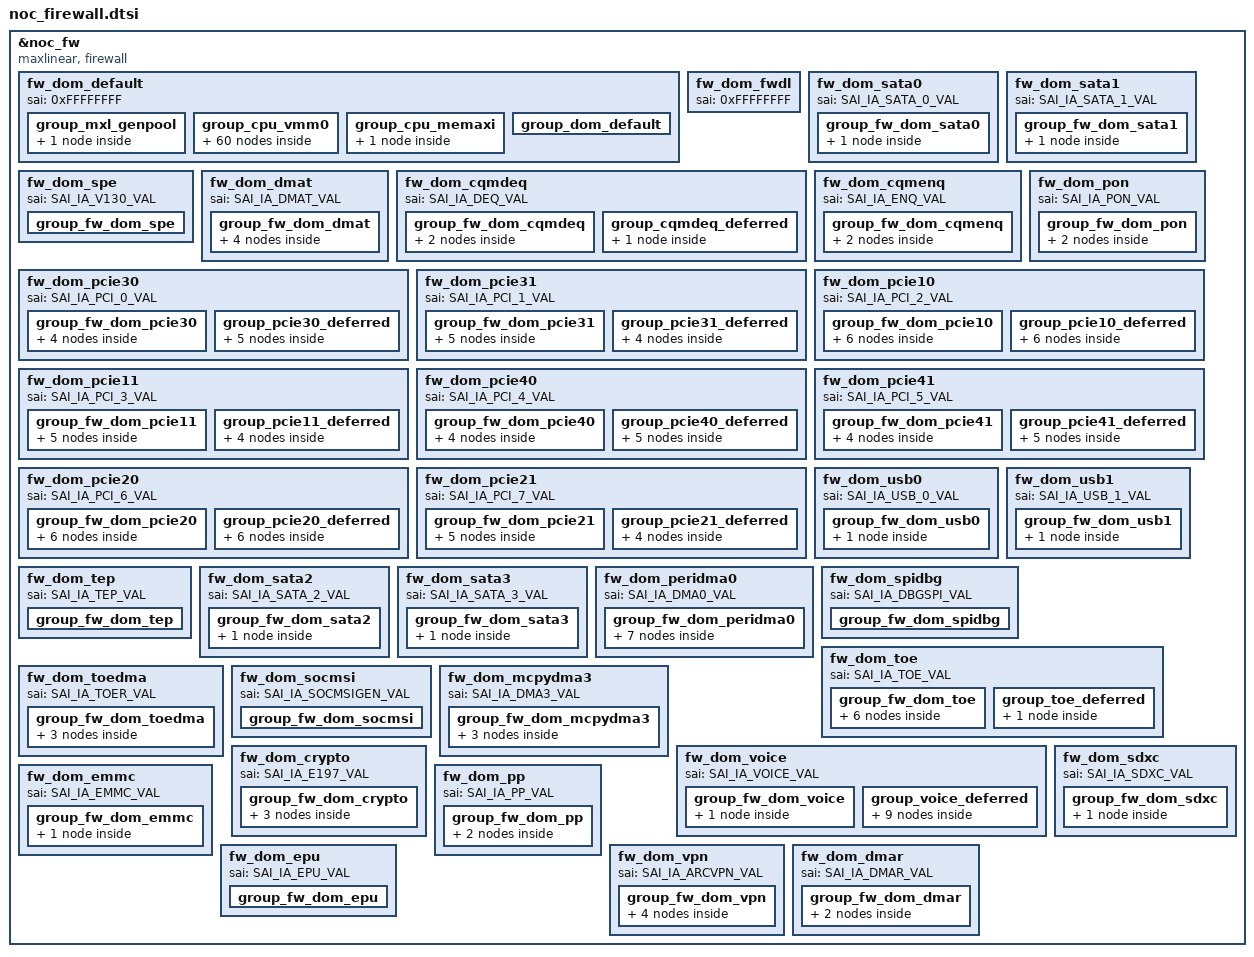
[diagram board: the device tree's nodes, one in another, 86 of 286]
// SPDX-License-Identifier: GPL-2.0
/**
 * Copyright (C) 2021 - 2024 MaxLinear, Inc.
 */
/* Based on released V3.0.31 version on Sep/13/2024 from Ritesh*/

#include <dt-bindings/soc/mxl,noc_fw_defs.h>

&noc_fw {
	compatible = "maxlinear, firewall";
	intel,socpool = <&cpu_pool &sys_pool &ro_pool &rw_pool &icc_pool>;

/* fw_dom_default must be defined in the DT */
	fw_dom_default:fw_dom_default {
		#firewall-domain-cells = <0>;
		sai = <0xFFFFFFFF>; /* special SAI */
		group_mxl_genpool {
		rule_mxl_genpool_1 { /*  8  in FW_DDR_Rules */
			op       = <NOC_FW_OP_MODIFY_SPLIT>;
			sai      = <SAI_IA_MEMAXI_VAL>;
			base     = <0xA0000000 NOC_FW_SYSPOOL_START>; /* NOC_FW_NONCOHERENT|NOC_FW_SPECIAL_REGION  NOC_FW_SYSPOOL_START */
			end      = <0xA0000000 NOC_FW_ROPOOL_END>; /* NOC_FW_NONCOHERENT|NOC_FW_SPECIAL_REGION  NOC_FW_ROPOOL_END */
			perm     = <NOC_FW_F_R>;
		};
		};
		group_cpu_vmm0 {
		rule_cpu_vmm0_1 { /*  12  in FW_LBAXI_Rules */
			op       = <NOC_FW_OP_ADD>;
			sai      = <ALL_SAI_IA_VMM_VAL>;
			target   = <&crypto>;
			base     = <0x0  0xED600000>;
			end      = <0x0  0xED6FFFFF>;
			perm     = <NOC_FW_F_RW>;
		};
		rule_cpu_vmm0_2 { /*  14  in FW_LBAXI_Rules */
			op       = <NOC_FW_OP_ADD>;
			sai      = <ALL_SAI_IA_VMM_VAL>;
			target   = <&mcpy>;
			base     = <0x0  0xED700000>;
			end      = <0x0  0xED70FFFF>;
			perm     = <NOC_FW_F_RW>;
		};
		rule_cpu_vmm0_3 { /*  15  in FW_LBAXI_Rules */
			op       = <NOC_FW_OP_ADD>;
			sai      = <ALL_SAI_IA_VMM_VAL>;
			target   = <&mcpy>;
			base     = <0x0  0xEC800000>;
			end      = <0x0  0xEC800FFF>;
			perm     = <NOC_FW_F_RW>;
		};
		rule_cpu_vmm0_4 { /*  16  in FW_LBAXI_Rules */
			op       = <NOC_FW_OP_ADD>;
			sai      = <ALL_SAI_IA_VMM_VAL>;
			target   = <&toe>;
			base     = <0x0  0xEC900000>;
			end      = <0x0  0xECBFFFFF>;
			perm     = <NOC_FW_F_RW>;
		};
		rule_cpu_vmm0_5 { /*  22  in FW_LBAXI_Rules */
			op       = <NOC_FW_OP_ADD>;
			sai      = <ALL_SAI_IA_VMM_VAL>;
			target   = <&sdxc>;
			base     = <0x0  0xEC600000>;
			end      = <0x0  0xEC6FFFFF>;
			perm     = <NOC_FW_F_RW>;
		};
		rule_cpu_vmm0_6 { /*  23  in FW_LBAXI_Rules */
			op       = <NOC_FW_OP_ADD>;
			sai      = <ALL_SAI_IA_VMM_VAL>;
			target   = <&ssx_voice>;
			base     = <0x0  0xED200000>;
			end      = <0x0  0xED480FFF>;
			perm     = <NOC_FW_F_RW>;
		};
		rule_cpu_vmm0_7 { /*  24  in FW_LBAXI_Rules */
			op       = <NOC_FW_OP_ADD>;
			sai      = <ALL_SAI_IA_VMM_VAL>;
			target   = <&combophy2>;
			base     = <0x0  0xC0A00000>;
			end      = <0x0  0xC0B43FFF>;
			perm     = <NOC_FW_F_RW>;
		};
		rule_cpu_vmm0_8 { /*  25  in FW_LBAXI_Rules */
			op       = <NOC_FW_OP_ADD>;
			sai      = <ALL_SAI_IA_VMM_VAL>;
			base     = <0x0  0xC0E00000>;
			end      = <0x0  0xC11FFFFF>;
			perm     = <NOC_FW_F_RW>;
		};

#ifndef LGMC_SOC
		rule_cpu_vmm0_9 { /*  29  in FW_LBAXI_Rules */
			op       = <NOC_FW_OP_ADD>;
			sai      = <ALL_SAI_IA_VMM_VAL>;
			target   = <&sata20>;
			base     = <0x0  0xC1A00000>;
			end      = <0x0  0xC1A000FF>;
			perm     = <NOC_FW_F_RW>;
		};
		rule_cpu_vmm0_10 { /*  30  in FW_LBAXI_Rules */
			op       = <NOC_FW_OP_ADD>;
			sai      = <ALL_SAI_IA_VMM_VAL>;
			target   = <&sata21>;
			base     = <0x0  0xC1B00000>;
			end      = <0x0  0xC1B000FF>;
			perm     = <NOC_FW_F_RW>;
		};
#endif

		rule_cpu_vmm0_11 { /*  31  in FW_LBAXI_Rules */
			op       = <NOC_FW_OP_ADD>;
			sai      = <ALL_SAI_IA_VMM_VAL>;
			target   = <&combophy0>;
			base     = <0x0  0xD0A00000>;
			end      = <0x0  0xD0B43FFF>;
			perm     = <NOC_FW_F_RW>;
		};
		rule_cpu_vmm0_12 { /*  32  in FW_LBAXI_Rules */
			op       = <NOC_FW_OP_ADD>;
			sai      = <ALL_SAI_IA_VMM_VAL>;
			base     = <0x0  0xD0E00000>;
			end      = <0x0  0xD11FFFFF>;
			perm     = <NOC_FW_F_RW>;
		};

#ifndef LGMC_SOC
		rule_cpu_vmm0_13 { /*  36  in FW_LBAXI_Rules */
			op       = <NOC_FW_OP_ADD>;
			sai      = <ALL_SAI_IA_VMM_VAL>;
			target   = <&sata10>;
			base     = <0x0  0xD1A00000>;
			end      = <0x0  0xD1A000FF>;
			perm     = <NOC_FW_F_RW>;
		};
		rule_cpu_vmm0_14 { /*  37  in FW_LBAXI_Rules */
			op       = <NOC_FW_OP_ADD>;
			sai      = <ALL_SAI_IA_VMM_VAL>;
			target   = <&sata11>;
			base     = <0x0  0xD1B00000>;
			end      = <0x0  0xD1B000FF>;
			perm     = <NOC_FW_F_RW>;
		};
#endif

		rule_cpu_vmm0_15 { /*  50  in FW_LBAXI_Rules */
			op       = <NOC_FW_OP_ADD>;
			sai      = <ALL_SAI_IA_VMM_VAL>;
			target   = <&ponmbox>;
			base     = <0x0  0xE7500000>;
			end      = <0x0  0xE7840FFF>;
			perm     = <NOC_FW_F_RW>;
		};
		rule_cpu_vmm0_16 { /*  51  in FW_LBAXI_Rules */
			op       = <NOC_FW_OP_ADD>;
			sai      = <ALL_SAI_IA_VMM_VAL>;
			target   = <&wan_xpcs>;
			base     = <0x0  0xE7842000>;
			end      = <0x0  0xE78440FF>;
			perm     = <NOC_FW_F_RW>;
		};
		rule_cpu_vmm0_17 { /*  52  in FW_LBAXI_Rules */
			op       = <NOC_FW_OP_ADD>;
			sai      = <ALL_SAI_IA_VMM_VAL>;
			target   = <&vpn>;
			base     = <0x0  0xE7B00000>;
			end      = <0x0  0xE7B01FFF>;
			perm     = <NOC_FW_F_RW>;
		};

#ifndef LGMC_SOC
		rule_cpu_vmm0_18 { /*  53  in FW_LBAXI_Rules */
			op       = <NOC_FW_OP_ADD>;
			sai      = <ALL_SAI_IA_VMM_VAL>;
			target   = <&usb0>;
			base     = <0x0  0xE7D00000>;
			end      = <0x0  0xE7D0DFFF>;
			perm     = <NOC_FW_F_RW>;
		};
		rule_cpu_vmm0_19 { /*  54  in FW_LBAXI_Rules */
			op       = <NOC_FW_OP_ADD>;
			sai      = <ALL_SAI_IA_VMM_VAL>;
			target   = <&usb0>;
			base     = <0x0  0xE7E00000>;
			end      = <0x0  0xE7E02FFF>;
			perm     = <NOC_FW_F_RW>;
		};
#endif

		rule_cpu_vmm0_20 { /*  55  in FW_LBAXI_Rules */
			op       = <NOC_FW_OP_ADD>;
			sai      = <ALL_SAI_IA_VMM_VAL>;
			target   = <&usb1>;
			base     = <0x0  0xE6E00000>;
			end      = <0x0  0xE6E0DFFF>;
			perm     = <NOC_FW_F_RW>;
		};
		rule_cpu_vmm0_21 { /*  56  in FW_LBAXI_Rules */
			op       = <NOC_FW_OP_ADD>;
			sai      = <ALL_SAI_IA_VMM_VAL>;
			target   = <&usb1>;
			base     = <0x0  0xE6F00000>;
			end      = <0x0  0xE6F02FFF>;
			perm     = <NOC_FW_F_RW>;
		};
		rule_cpu_vmm0_22 { /*  58  in FW_LBAXI_Rules */
			status = "disabled"; /* TEP_DEBUG2 */
			op       = <NOC_FW_OP_ADD>;
			sai      = <ALL_SAI_IA_VMM_VAL>;
			base     = <0x0  0xE0000000>;
			end      = <0x0  0xE0020FFF>;
			perm     = <NOC_FW_F_RW>;
		};
		rule_cpu_vmm0_23 { /*  59  in FW_LBAXI_Rules */
			op       = <NOC_FW_OP_MODIFY>;
			sai      = <ALL_SAI_IA_VMM_VAL>;
			base     = <0x0  0xE00E0000>;
			end      = <0x0  0xE00E0FFF>;
			perm     = <NOC_FW_F_RW>;
		};
		rule_cpu_vmm0_24 { /*  60  in FW_LBAXI_Rules */
			op       = <NOC_FW_OP_ADD>;
			sai      = <ALL_SAI_IA_VMM_VAL>;
			base     = <0x0  0xECF00000>;
			end      = <0x0  0xECF04FFF>;
			perm     = <NOC_FW_F_RW>;
		};
		rule_cpu_vmm0_25 { /*  65  in FW_LBAXI_Rules */
			op       = <NOC_FW_OP_ADD>;
			sai      = <ALL_SAI_IA_VMM_VAL>;
			base     = <0x0  0xE7140000>;
			end      = <0x0  0xE7153FFF>;
			perm     = <NOC_FW_F_RW>;
		};
		rule_cpu_vmm0_26 { /*  66  in FW_LBAXI_Rules */
			op       = <NOC_FW_OP_ADD>;
			sai      = <ALL_SAI_IA_VMM_VAL>;
			base     = <0x0  0xE7200000>;
			end      = <0x0  0xE7300FFF>;
			perm     = <NOC_FW_F_RW>;
		};
		rule_cpu_vmm0_27 { /*  67  in FW_LBAXI_Rules */
			op       = <NOC_FW_OP_ADD>;
			sai      = <ALL_SAI_IA_VMM_VAL>;
			target   = <&dma2tx>;
			base     = <0x0  0xE7000000>;
			end      = <0x0  0xE7000FFF>;
			perm     = <NOC_FW_F_RW>;
		};
		rule_cpu_vmm0_28 { /*  68  in FW_LBAXI_Rules */
			op       = <NOC_FW_OP_ADD>;
			sai      = <ALL_SAI_IA_VMM_VAL>;
			target   = <&dma0tx>;
			base     = <0x0  0xE7700000>;
			end      = <0x0  0xE7700FFF>;
			perm     = <NOC_FW_F_RW>;
		};
		rule_cpu_vmm0_29 { /*  69  in FW_LBAXI_Rules */
			op       = <NOC_FW_OP_ADD>;
			sai      = <ALL_SAI_IA_VMM_VAL>;
			base     = <0x0  0xE7600000>;
			end      = <0x0  0xE7642FFF>;
			perm     = <NOC_FW_F_RW>;
		};
		rule_cpu_vmm0_30 { /*  70  in FW_LBAXI_Rules */
			op       = <NOC_FW_OP_ADD>;
			sai      = <ALL_SAI_IA_VMM_VAL>;
			base     = <0x0  0xE7400000>;
			end      = <0x0  0xE742FFFF>;
			perm     = <NOC_FW_F_RW>;
		};
		rule_cpu_vmm0_31 { /*  72  in FW_LBAXI_Rules */
			op       = <NOC_FW_OP_ADD>;
			sai      = <ALL_SAI_IA_VMM_VAL>;
			base     = <0x0  0xD4000000>;
			end      = <0x0  0xDFFFFFFF>;
			perm     = <NOC_FW_F_RW>;
		};
		rule_cpu_vmm0_32 { /*  76  in FW_LBAXI_Rules */
			op       = <NOC_FW_OP_ADD>;
			sai      = <ALL_SAI_IA_VMM_VAL>;
			base     = <0x0  0xC4000000>;
			end      = <0x0  0xCFFFFFFF>;
			perm     = <NOC_FW_F_RW>;
		};
		rule_cpu_vmm0_33 { /*  80  in FW_LBAXI_Rules */
			op       = <NOC_FW_OP_ADD>;
			sai      = <ALL_SAI_IA_VMM_VAL>;
			target   = <&ssx_voice>;
			base     = <0x0  0xED900000>;
			end      = <0x0  0xED980FFF>;
			perm     = <NOC_FW_F_RW>;
		};
		rule_cpu_vmm0_34 { /*  81  in FW_LBAXI_Rules */
			op       = <NOC_FW_OP_ADD>;
			sai      = <ALL_SAI_IA_VMM_VAL>;
			target   = <&pcie10>;
			base     = <0x0  0xD2000000>;
			end      = <0x0  0xD21FFFFF>;
			perm     = <NOC_FW_F_RW>;
		};
		rule_cpu_vmm0_35 { /*  82  in FW_LBAXI_Rules */
			op       = <NOC_FW_OP_ADD>;
			sai      = <ALL_SAI_IA_VMM_VAL>;
			target   = <&pcie11>;
			base     = <0x0  0xD2800000>;
			end      = <0x0  0xD29FFFFF>;
			perm     = <NOC_FW_F_RW>;
		};
		rule_cpu_vmm0_36 { /*  83  in FW_LBAXI_Rules */
			op       = <NOC_FW_OP_ADD>;
			sai      = <ALL_SAI_IA_VMM_VAL>;
			target   = <&pcie30>;
			base     = <0x0  0xD3000000>;
			end      = <0x0  0xD31FFFFF>;
			perm     = <NOC_FW_F_RW>;
		};
		rule_cpu_vmm0_37 { /*  84  in FW_LBAXI_Rules */
			op       = <NOC_FW_OP_ADD>;
			sai      = <ALL_SAI_IA_VMM_VAL>;
			target   = <&pcie31>;
			base     = <0x0  0xD3800000>;
			end      = <0x0  0xD39FFFFF>;
			perm     = <NOC_FW_F_RW>;
		};
		rule_cpu_vmm0_38 { /*  85  in FW_LBAXI_Rules */
			op       = <NOC_FW_OP_ADD>;
			sai      = <ALL_SAI_IA_VMM_VAL>;
			target   = <&pcie20>;
			base     = <0x0  0xC2000000>;
			end      = <0x0  0xC21FFFFF>;
			perm     = <NOC_FW_F_RW>;
		};
		rule_cpu_vmm0_39 { /*  86  in FW_LBAXI_Rules */
			op       = <NOC_FW_OP_ADD>;
			sai      = <ALL_SAI_IA_VMM_VAL>;
			target   = <&pcie21>;
			base     = <0x0  0xC2800000>;
			end      = <0x0  0xC29FFFFF>;
			perm     = <NOC_FW_F_RW>;
		};
		rule_cpu_vmm0_40 { /*  87  in FW_LBAXI_Rules */
			op       = <NOC_FW_OP_ADD>;
			sai      = <ALL_SAI_IA_VMM_VAL>;
			target   = <&pcie40>;
			base     = <0x0  0xC3000000>;
			end      = <0x0  0xC31FFFFF>;
			perm     = <NOC_FW_F_RW>;
		};
		rule_cpu_vmm0_41 { /*  88  in FW_LBAXI_Rules */
			op       = <NOC_FW_OP_ADD>;
			sai      = <ALL_SAI_IA_VMM_VAL>;
			target   = <&pcie41>;
			base     = <0x0  0xC3800000>;
			end      = <0x0  0xC39FFFFF>;
			perm     = <NOC_FW_F_RW>;
		};
		rule_cpu_vmm0_42 { /*  92  in FW_LBAXI_Rules */
			op       = <NOC_FW_OP_ADD>;
			sai      = <ALL_SAI_IA_VMM_VAL>;
			target   = <&i2s1>;
			base     = <0x0  0xE2700000>;
			end      = <0x0  0xE270FFFF>;
			perm     = <NOC_FW_F_RW>;
		};
		rule_cpu_vmm0_43 { /*  96  in FW_LBAXI_Rules */
			op       = <NOC_FW_OP_ADD>;
			sai      = <ALL_SAI_IA_VMM_VAL>;
			target   = <&ssc0>;
			base     = <0x0  0xE0800000>;
			end      = <0x0  0xE0800FFF>;
			perm     = <NOC_FW_F_RW>;
		};
		rule_cpu_vmm0_44 { /*  97  in FW_LBAXI_Rules */
			op       = <NOC_FW_OP_ADD>;
			sai      = <ALL_SAI_IA_VMM_VAL>;
			target   = <&ssc1>;
			base     = <0x0  0xE0900000>;
			end      = <0x0  0xE0900FFF>;
			perm     = <NOC_FW_F_RW>;
		};
		rule_cpu_vmm0_45 { /*  100  in FW_LBAXI_Rules */
			op       = <NOC_FW_OP_MODIFY>;
			sai      = <ALL_SAI_IA_VMM_VAL>;
			target   = <&asc0>;
			base     = <0x0  0xE0A00000>;
			end      = <0x0  0xE0A00FFF>;
			perm     = <NOC_FW_F_RW>;
		};
		rule_cpu_vmm0_46 { /*  102  in FW_LBAXI_Rules */
			op       = <NOC_FW_OP_ADD>;
			sai      = <ALL_SAI_IA_VMM_VAL>;
			target   = <&asc1>;
			base     = <0x0  0xE0C00000>;
			end      = <0x0  0xE0C00FFF>;
			perm     = <NOC_FW_F_RW>;
		};
		rule_cpu_vmm0_47 { /*  103  in FW_LBAXI_Rules */
			op       = <NOC_FW_OP_ADD>;
			sai      = <ALL_SAI_IA_VMM_VAL>;
			target   = <&fan0>;
			base     = <0x0  0xE0D00000>;
			end      = <0x0  0xE0D00FFF>;
			perm     = <NOC_FW_F_RW>;
		};
		rule_cpu_vmm0_48 { /*  105  in FW_LBAXI_Rules */
			op       = <NOC_FW_OP_ADD>;
			sai      = <ALL_SAI_IA_VMM_VAL>;
			target   = <&ebu_nand>;
			base     = <0x0  0xE0F00000>;
			end      = <0x0  0xE10FFFFF>;
			perm     = <NOC_FW_F_RW>;
		};
		rule_cpu_vmm0_49 { /*  106  in FW_LBAXI_Rules */
			op       = <NOC_FW_OP_ADD>;
			sai      = <ALL_SAI_IA_VMM_VAL>;
			target   = <&asc2>;
			base     = <0x0  0xE1100000>;
			end      = <0x0  0xE1100FFF>;
			perm     = <NOC_FW_F_RW>;
		};
		rule_cpu_vmm0_50 { /*  107  in FW_LBAXI_Rules */
			op       = <NOC_FW_OP_ADD>;
			sai      = <ALL_SAI_IA_VMM_VAL>;
			target   = <&i2c1>;
			base     = <0x0  0xE1300000>;
			end      = <0x0  0xE1300FFF>;
			perm     = <NOC_FW_F_RW>;
		};
		rule_cpu_vmm0_51 { /*  108  in FW_LBAXI_Rules */
			op       = <NOC_FW_OP_ADD>;
			sai      = <ALL_SAI_IA_VMM_VAL>;
			target   = <&ebu_nand>;
			base     = <0x0  0xE1400000>;
			end      = <0x0  0xE1C0FFFF>;
			perm     = <NOC_FW_F_RW>;
		};
		rule_cpu_vmm0_52 { /*  109  in FW_LBAXI_Rules */
			op       = <NOC_FW_OP_ADD>;
			sai      = <ALL_SAI_IA_VMM_VAL>;
			target   = <&ssc2>;
			base     = <0x0  0xE1D00000>;
			end      = <0x0  0xE1D00FFF>;
			perm     = <NOC_FW_F_RW>;
		};
		rule_cpu_vmm0_53 { /*  110  in FW_LBAXI_Rules */
			op       = <NOC_FW_OP_ADD>;
			sai      = <ALL_SAI_IA_VMM_VAL>;
			target   = <&ssc3>;
			base     = <0x0  0xE1E00000>;
			end      = <0x0  0xE1E00FFF>;
			perm     = <NOC_FW_F_RW>;
		};
		rule_cpu_vmm0_54 { /*  111  in FW_LBAXI_Rules */
			op       = <NOC_FW_OP_ADD>;
			sai      = <ALL_SAI_IA_VMM_VAL>;
			target   = <&i2c2>;
			base     = <0x0  0xE1F00000>;
			end      = <0x0  0xE1F00FFF>;
			perm     = <NOC_FW_F_RW>;
		};
		rule_cpu_vmm0_55 { /*  112  in FW_LBAXI_Rules */
			op       = <NOC_FW_OP_ADD>;
			sai      = <ALL_SAI_IA_VMM_VAL>;
			target   = <&i2c3>;
			base     = <0x0  0xE2000000>;
			end      = <0x0  0xE2000FFF>;
			perm     = <NOC_FW_F_RW>;
		};
		rule_cpu_vmm0_56 { /*  113  in FW_LBAXI_Rules */
			op       = <NOC_FW_OP_ADD>;
			sai      = <ALL_SAI_IA_VMM_VAL>;
			target   = <&i2s0>;
			base     = <0x0  0xE2100000>;
			end      = <0x0  0xE210FFFF>;
			perm     = <NOC_FW_F_RW>;
		};
		rule_cpu_vmm0_57 { /*  114  in FW_LBAXI_Rules */
			op       = <NOC_FW_OP_ADD>;
			sai      = <ALL_SAI_IA_VMM_VAL>;
			target   = <&wan_xpcs>;
			base     = <0x0  0xE7800000>;
			end      = <0x0  0xE7840FFF>;
			perm     = <NOC_FW_F_RW>;
		};
		rule_cpu_vmm0_58 { /*  116  in FW_LBAXI_Rules */
			op       = <NOC_FW_OP_ADD>;
			sai      = <ALL_SAI_IA_VMM_VAL>;
			target   = <&combophy3>;
			base     = <0x0  0xC0C00000>;
			end      = <0x0  0xC0D43FFF>;
			perm     = <NOC_FW_F_RW>;
		};
		rule_cpu_vmm0_59 { /*  117  in FW_LBAXI_Rules */
			op       = <NOC_FW_OP_ADD>;
			sai      = <ALL_SAI_IA_VMM_VAL>;
			target   = <&combophy1>;
			base     = <0x0  0xD0C00000>;
			end      = <0x0  0xD0D43FFF>;
			perm     = <NOC_FW_F_RW>;
		};
		rule_cpu_vmm0_60 { /*  118  in FW_LBAXI_Rules */
			op       = <NOC_FW_OP_ADD>;
			sai      = <ALL_SAI_IA_VMM_VAL>;
			target   = <&dma0>;
			base     = <0x0  0xE0E00000>;
			end      = <0x0  0xE0E0FFFF>;
			perm     = <NOC_FW_F_RW>;
		};
		};
		group_cpu_memaxi {
		rule_cpu_memaxi_1 { /*  15  in FW_DDR_Rules */
			op       = <NOC_FW_OP_ADD>;
			sai      = <SAI_IA_MEMAXI_VAL>;
			base     = <0xC  0xC00000>;
			end      = <0xC  0xFFFFFF>;
			perm     = <NOC_FW_F_RW>;
		};
		};
		group_dom_default {
		};
	};
	fw_dom_fwdl: fw_dom_fwdl {
		sai = <0xFFFFFFFF>;
		#firewall-domain-cells = <0>;
	};

#ifndef LGMC_SOC
	fw_dom_sata0:fw_dom_sata0 {
		#firewall-domain-cells = <0>;
		sai = <SAI_IA_SATA_0_VAL>;
		group_fw_dom_sata0 {
		rule_fw_dom_sata0_1 { /*  39  in FW_HSIOL_Rules */
			op       = <NOC_FW_OP_ADD>;
			sai      = <SAI_IA_SATA_0_VAL>;
			base     = <NOC_FW_SPECIAL_REGION  NOC_FW_DDR_GENERIC_RW_START>;
			end      = <NOC_FW_SPECIAL_REGION  NOC_FW_DDR_GENERIC_RW_END>;
			perm     = <NOC_FW_F_RW>;
		};
		};
	};

	fw_dom_sata1:fw_dom_sata1 {
		#firewall-domain-cells = <0>;
		sai = <SAI_IA_SATA_1_VAL>;
		group_fw_dom_sata1 {
		rule_fw_dom_sata1_1 { /*  40  in FW_HSIOL_Rules */
			op       = <NOC_FW_OP_ADD>;
			sai      = <SAI_IA_SATA_1_VAL>;
			base     = <NOC_FW_SPECIAL_REGION  NOC_FW_DDR_GENERIC_RW_START>;
			end      = <NOC_FW_SPECIAL_REGION  NOC_FW_DDR_GENERIC_RW_END>;
			perm     = <NOC_FW_F_RW>;
		};
		};
	};
#endif

	fw_dom_spe:fw_dom_spe {
		#firewall-domain-cells = <0>;
		sai = <SAI_IA_V130_VAL>;
		group_fw_dom_spe {
		};
	};

	fw_dom_dmat:fw_dom_dmat {
		#firewall-domain-cells = <0>;
		sai = <SAI_IA_DMAT_VAL>;
		group_fw_dom_dmat {
		rule_fw_dom_dmat_1 { /*  4  in FW_SSB_Rules */
			op       = <NOC_FW_OP_ADD>;
			sai      = <SAI_IA_DMAT_VAL>;
			base     = <0x0  0xECD00000>;
			end      = <0x0  0xECD7FFFF>;
			perm     = <NOC_FW_F_RW>;
		};
		rule_fw_dom_dmat_2 { /*  9  in FW_ETHNoC_Rules */
			op       = <NOC_FW_OP_ADD>;
			sai      = <SAI_IA_DMAT_VAL>;
			base     = <0xA0000000 NOC_FW_SYSPOOL_START>; /* NOC_FW_NONCOHERENT|NOC_FW_SPECIAL_REGION  NOC_FW_SYSPOOL_START */
			end      = <0xA0000000 NOC_FW_SYSPOOL_END>; /* NOC_FW_NONCOHERENT|NOC_FW_SPECIAL_REGION  NOC_FW_SYSPOOL_END */
			perm     = <NOC_FW_F_R>;
		};
		rule_fw_dom_dmat_3 { /*  61  in FW_DDR_Rules */
			op       = <NOC_FW_OP_MODIFY>;
			sai      = <SAI_IA_DMAT_VAL>;
			base     = <NOC_FW_SPECIAL_REGION  NOC_FW_DDR_GENERIC_RW_START>;
			end      = <NOC_FW_SPECIAL_REGION  NOC_FW_DDR_GENERIC_RW_END>;
			perm     = <NOC_FW_F_RW>;
		};
		rule_fw_dom_dmat_4 { /*  62  in FW_DDR_Rules */
			op       = <NOC_FW_OP_ADD>;
			sai      = <SAI_IA_DMAT_VAL>;
			base     = <NOC_FW_SPECIAL_REGION  NOC_FW_CPUPOOL_START>;
			end      = <NOC_FW_SPECIAL_REGION  NOC_FW_CPUPOOL_END>;
			perm     = <NOC_FW_F_RW>;
		};
		};
	};
	fw_dom_cqmdeq:fw_dom_cqmdeq {
		#firewall-domain-cells = <0>;
		sai = <SAI_IA_DEQ_VAL>;
		group_fw_dom_cqmdeq {
		rule_fw_dom_cqmdeq_1 { /*  13  in FW_ETHNoC_Rules */
			op       = <NOC_FW_OP_ADD>;
			sai      = <SAI_IA_DEQ_VAL>;
			base     = <0xA0000000 NOC_FW_SYSPOOL_START>; /* NOC_FW_NONCOHERENT|NOC_FW_SPECIAL_REGION  NOC_FW_SYSPOOL_START */
			end      = <0xA0000000 NOC_FW_SYSPOOL_END>; /* NOC_FW_NONCOHERENT|NOC_FW_SPECIAL_REGION  NOC_FW_SYSPOOL_END */
			perm     = <NOC_FW_F_RW>;
		};
		rule_fw_dom_cqmdeq_2 { /*  65  in FW_DDR_Rules */
			op       = <NOC_FW_OP_ADD>;
			sai      = <SAI_IA_DEQ_VAL>;
			base     = <NOC_FW_SPECIAL_REGION  NOC_FW_CPUPOOL_START>;
			end      = <NOC_FW_SPECIAL_REGION  NOC_FW_CPUPOOL_END>;
			perm     = <NOC_FW_F_RW>;
		};
		};
		group_cqmdeq_deferred {
		rule_cqmdeq_deferred_1 { /*  63  in FW_DDR_Rules */
			op       = <NOC_FW_OP_ADD>;
			sai      = <SAI_IA_DEQ_VAL>;
			base     = <NOC_FW_SPECIAL_REGION_DYN  NOC_FW_DYN_CPUBUFRET_START>;
			end      = <NOC_FW_SPECIAL_REGION_DYN  NOC_FW_DYN_CPUBUFRET_END>;
			perm     = <NOC_FW_F_RW>;
			deferred;
		};
		};
	};
	fw_dom_cqmenq:fw_dom_cqmenq {
		#firewall-domain-cells = <0>;
		sai = <SAI_IA_ENQ_VAL>;
		group_fw_dom_cqmenq {
		rule_fw_dom_cqmenq_1 { /*  14  in FW_ETHNoC_Rules */
			op       = <NOC_FW_OP_ADD>;
			sai      = <SAI_IA_ENQ_VAL>;
			base     = <0xA0000000 NOC_FW_SYSPOOL_START>; /* NOC_FW_NONCOHERENT|NOC_FW_SPECIAL_REGION  NOC_FW_SYSPOOL_START */
			end      = <0xA0000000 NOC_FW_SYSPOOL_END>; /* NOC_FW_NONCOHERENT|NOC_FW_SPECIAL_REGION  NOC_FW_SYSPOOL_END */
			perm     = <NOC_FW_F_RW>;
		};
		rule_fw_dom_cqmenq_2 { /*  67  in FW_DDR_Rules */
			op       = <NOC_FW_OP_ADD>;
			sai      = <SAI_IA_ENQ_VAL>;
			base     = <NOC_FW_SPECIAL_REGION  NOC_FW_CPUPOOL_START>;
			end      = <NOC_FW_SPECIAL_REGION  NOC_FW_CPUPOOL_END>;
			perm     = <NOC_FW_F_RW>;
		};
		};
	};
	fw_dom_pon:fw_dom_pon {
		#firewall-domain-cells = <0>;
		sai = <SAI_IA_PON_VAL>;
		group_fw_dom_pon {
		rule_fw_dom_pon_1 { /*  71  in FW_PERI_Rules */
			op       = <NOC_FW_OP_ADD>;
			sai      = <SAI_IA_PON_VAL>;
			base     = <0x0  0xE0200000>;
			end      = <0x0  0xE02FFFFF>;
			perm     = <NOC_FW_F_RW>;
		};
		rule_fw_dom_pon_2 { /*  79  in FW_PERI_Rules */
			op       = <NOC_FW_OP_ADD>;
			sai      = <SAI_IA_PON_VAL>;
			base     = <0x0  0xECC80000>;
			end      = <0x0  0xECC80FFF>;
			perm     = <NOC_FW_F_R>;
		};
		};
	};
	fw_dom_pcie30:fw_dom_pcie30 {
		#firewall-domain-cells = <0>;
		sai = <SAI_IA_PCI_0_VAL>;
		group_fw_dom_pcie30 {
		rule_fw_dom_pcie30_1 { /*  4  in FW_HSIOL_Rules */
			op       = <NOC_FW_OP_ADD>;
			sai      = <SAI_IA_PCI_0_VAL>;
			base     = <0xA0000000 NOC_FW_SYSPOOL_START>; /* NOC_FW_NONCOHERENT|NOC_FW_SPECIAL_REGION  NOC_FW_SYSPOOL_START */
			end      = <0xA0000000 NOC_FW_SYSPOOL_END>; /* NOC_FW_NONCOHERENT|NOC_FW_SPECIAL_REGION  NOC_FW_SYSPOOL_END */
			perm     = <NOC_FW_F_RW>;
		};
		rule_fw_dom_pcie30_2 { /*  8  in FW_HSIOL_Rules */
			op       = <NOC_FW_OP_ADD>;
			sai      = <SAI_IA_PCI_0_VAL>;
			base     = <NOC_FW_SPECIAL_REGION  NOC_FW_DDR_GENERIC_RW_START>;
			end      = <NOC_FW_SPECIAL_REGION  NOC_FW_DDR_GENERIC_RW_END>;
			perm     = <NOC_FW_F_RW>;
		};
		rule_fw_dom_pcie30_3 { /*  9  in FW_HSIOL_Rules */
			op       = <NOC_FW_OP_ADD>;
			sai      = <SAI_IA_PCI_0_VAL>;
			base     = <0xA0000000 NOC_FW_DDR_GENERIC_RW_START>; /* NOC_FW_NONCOHERENT|NOC_FW_SPECIAL_REGION  NOC_FW_DDR_GENERIC_RW_START */
			end      = <0xA0000000 NOC_FW_DDR_GENERIC_RW_END>; /* NOC_FW_NONCOHERENT|NOC_FW_SPECIAL_REGION  NOC_FW_DDR_GENERIC_RW_END */
			perm     = <NOC_FW_F_RW>;
		};
		rule_fw_dom_pcie30_4 { /*  11  in FW_HSIOL_Rules */
			op       = <NOC_FW_OP_ADD>;
			sai      = <SAI_IA_PCI_0_VAL>;
			base     = <0x0  0xFEE00000>;
			end      = <0x0  0xFEEFFFFF>;
			perm     = <NOC_FW_F_RW>;
		};
		};
		group_pcie30_deferred {
		rule_pcie30_deferred_1 { /*  5  in FW_HSIOL_Rules */
			op       = <NOC_FW_OP_ADD>;
			sai      = <SAI_IA_PCI_0_VAL>;
			base     = <NOC_FW_SPECIAL_REGION_DYN  NOC_FW_DYN_PCIE30_CQM_DCEQ_PORT_START>;
			end      = <NOC_FW_SPECIAL_REGION_DYN  NOC_FW_DYN_PCIE30_CQM_DCEQ_PORT_END>;
			perm     = <NOC_FW_F_RW>;
			deferred;
		};
		rule_pcie30_deferred_2 { /*  6  in FW_HSIOL_Rules */
			op       = <NOC_FW_OP_ADD>;
			sai      = <SAI_IA_PCI_0_VAL>;
			base     = <NOC_FW_SPECIAL_REGION_DYN  NOC_FW_DYN_PCIE30_CQM_DCDQ_PORT_START>;
			end      = <NOC_FW_SPECIAL_REGION_DYN  NOC_FW_DYN_PCIE30_CQM_DCDQ_PORT_END>;
			perm     = <NOC_FW_F_RW>;
			deferred;
		};
		rule_pcie30_deferred_3 { /*  7  in FW_HSIOL_Rules */
			op       = <NOC_FW_OP_ADD>;
			sai      = <SAI_IA_PCI_0_VAL>;
			base     = <NOC_FW_SPECIAL_REGION_DYN  NOC_FW_DYN_PCIE30_BM_START>;
			end      = <NOC_FW_SPECIAL_REGION_DYN  NOC_FW_DYN_PCIE30_BM_END>;
			perm     = <NOC_FW_F_RW>;
			deferred;
		};
		rule_pcie30_deferred_4 { /*  64  in FW_PERI_Rules */
			op       = <NOC_FW_OP_ADD>;
			sai      = <SAI_IA_DEQ_VAL>;
			base     = <NOC_FW_SPECIAL_REGION_DYN  NOC_FW_DYN_PCIE30_PERI_UMT_START>;
			end      = <NOC_FW_SPECIAL_REGION_DYN  NOC_FW_DYN_PCIE30_PERI_UMT_END>;
			perm     = <NOC_FW_F_W>;
			deferred;
		};
		rule_pcie30_deferred_5 { /*  82  in FW_PERI_Rules */
			op       = <NOC_FW_OP_ADD>;
			sai      = <SAI_IA_ARCVPN_VAL>;
			base     = <NOC_FW_SPECIAL_REGION_DYN  NOC_FW_DYN_PCIE30_PERI_UMT_START>;
			end      = <NOC_FW_SPECIAL_REGION_DYN  NOC_FW_DYN_PCIE30_PERI_UMT_END>;
			perm     = <NOC_FW_F_W>;
			deferred;
		};
		};
	};
	fw_dom_pcie31:fw_dom_pcie31 {
		#firewall-domain-cells = <0>;
		sai = <SAI_IA_PCI_1_VAL>;
		group_fw_dom_pcie31 {
		rule_fw_dom_pcie31_1 { /*  12  in FW_HSIOL_Rules */
			op       = <NOC_FW_OP_ADD>;
			sai      = <SAI_IA_PCI_1_VAL>;
			base     = <0xA0000000 NOC_FW_SYSPOOL_START>; /* NOC_FW_NONCOHERENT|NOC_FW_SPECIAL_REGION  NOC_FW_SYSPOOL_START */
			end      = <0xA0000000 NOC_FW_SYSPOOL_END>; /* NOC_FW_NONCOHERENT|NOC_FW_SPECIAL_REGION  NOC_FW_SYSPOOL_END */
			perm     = <NOC_FW_F_RW>;
		};
		rule_fw_dom_pcie31_2 { /*  15  in FW_HSIOL_Rules */
			op       = <NOC_FW_OP_ADD>;
			sai      = <SAI_IA_PCI_1_VAL>;
			base     = <NOC_FW_SPECIAL_REGION_DYN  NOC_FW_DYN_PCIE31_BM_START>;
			end      = <NOC_FW_SPECIAL_REGION_DYN  NOC_FW_DYN_PCIE31_BM_END>;
			perm     = <NOC_FW_F_RW>;
		};
		rule_fw_dom_pcie31_3 { /*  16  in FW_HSIOL_Rules */
			op       = <NOC_FW_OP_ADD>;
			sai      = <SAI_IA_PCI_1_VAL>;
			base     = <NOC_FW_SPECIAL_REGION  NOC_FW_DDR_GENERIC_RW_START>;
			end      = <NOC_FW_SPECIAL_REGION  NOC_FW_DDR_GENERIC_RW_END>;
			perm     = <NOC_FW_F_RW>;
		};
		rule_fw_dom_pcie31_4 { /*  17  in FW_HSIOL_Rules */
			op       = <NOC_FW_OP_ADD>;
			sai      = <SAI_IA_PCI_1_VAL>;
			base     = <0xA0000000 NOC_FW_DDR_GENERIC_RW_START>; /* NOC_FW_NONCOHERENT|NOC_FW_SPECIAL_REGION  NOC_FW_DDR_GENERIC_RW_START */
			end      = <0xA0000000 NOC_FW_DDR_GENERIC_RW_END>; /* NOC_FW_NONCOHERENT|NOC_FW_SPECIAL_REGION  NOC_FW_DDR_GENERIC_RW_END */
			perm     = <NOC_FW_F_RW>;
		};
		rule_fw_dom_pcie31_5 { /*  19  in FW_HSIOL_Rules */
			op       = <NOC_FW_OP_ADD>;
			sai      = <SAI_IA_PCI_1_VAL>;
			base     = <0x0  0xFEE00000>;
			end      = <0x0  0xFEEFFFFF>;
			perm     = <NOC_FW_F_RW>;
		};
		};
		group_pcie31_deferred {
		rule_pcie31_deferred_1 { /*  13  in FW_HSIOL_Rules */
			op       = <NOC_FW_OP_ADD>;
			sai      = <SAI_IA_PCI_1_VAL>;
			base     = <NOC_FW_SPECIAL_REGION_DYN  NOC_FW_DYN_PCIE31_CQM_DCEQ_PORT_START>;
			end      = <NOC_FW_SPECIAL_REGION_DYN  NOC_FW_DYN_PCIE31_CQM_DCEQ_PORT_END>;
			perm     = <NOC_FW_F_RW>;
			deferred;
		};
		rule_pcie31_deferred_2 { /*  14  in FW_HSIOL_Rules */
			op       = <NOC_FW_OP_ADD>;
			sai      = <SAI_IA_PCI_1_VAL>;
			base     = <NOC_FW_SPECIAL_REGION_DYN  NOC_FW_DYN_PCIE31_CQM_DCDQ_PORT_START>;
			end      = <NOC_FW_SPECIAL_REGION_DYN  NOC_FW_DYN_PCIE31_CQM_DCDQ_PORT_END>;
			perm     = <NOC_FW_F_RW>;
			deferred;
		};
		rule_pcie31_deferred_3 { /*  65  in FW_PERI_Rules */
			op       = <NOC_FW_OP_ADD>;
			sai      = <SAI_IA_DEQ_VAL>;
			base     = <NOC_FW_SPECIAL_REGION_DYN  NOC_FW_DYN_PCIE31_PERI_UMT_START>;
			end      = <NOC_FW_SPECIAL_REGION_DYN  NOC_FW_DYN_PCIE31_PERI_UMT_END>;
			perm     = <NOC_FW_F_W>;
			deferred;
		};
		rule_pcie31_deferred_4 { /*  83  in FW_PERI_Rules */
			op       = <NOC_FW_OP_ADD>;
			sai      = <SAI_IA_ARCVPN_VAL>;
			base     = <NOC_FW_SPECIAL_REGION_DYN  NOC_FW_DYN_PCIE31_PERI_UMT_START>;
			end      = <NOC_FW_SPECIAL_REGION_DYN  NOC_FW_DYN_PCIE31_PERI_UMT_END>;
			perm     = <NOC_FW_F_W>;
			deferred;
		};
		};
	};
	fw_dom_pcie10:fw_dom_pcie10 {
		#firewall-domain-cells = <0>;
		sai = <SAI_IA_PCI_2_VAL>;
		group_fw_dom_pcie10 {
		rule_fw_dom_pcie10_1 { /*  20  in FW_HSIOL_Rules */
			op       = <NOC_FW_OP_ADD>;
			sai      = <SAI_IA_PCI_2_VAL>;
			base     = <0xA0000000 NOC_FW_SYSPOOL_START>; /* NOC_FW_NONCOHERENT|NOC_FW_SPECIAL_REGION  NOC_FW_SYSPOOL_START */
			end      = <0xA0000000 NOC_FW_SYSPOOL_END>; /* NOC_FW_NONCOHERENT|NOC_FW_SPECIAL_REGION  NOC_FW_SYSPOOL_END */
			perm     = <NOC_FW_F_RW>;
		};
		rule_fw_dom_pcie10_2 { /*  21  in FW_HSIOL_Rules */
			op       = <NOC_FW_OP_ADD>;
			sai      = <SAI_IA_PCI_2_VAL>;
			base     = <NOC_FW_SPECIAL_REGION  NOC_FW_CPUPOOL_START>;
			end      = <NOC_FW_SPECIAL_REGION  NOC_FW_CPUPOOL_END>;
			perm     = <NOC_FW_F_RW>;
		};
		rule_fw_dom_pcie10_3 { /*  22  in FW_HSIOL_Rules */
			op       = <NOC_FW_OP_ADD>;
			sai      = <SAI_IA_PCI_2_VAL>;
			base     = <0xA0000000 NOC_FW_CPUPOOL_START>; /* NOC_FW_NONCOHERENT|NOC_FW_SPECIAL_REGION  NOC_FW_CPUPOOL_START */
			end      = <0xA0000000 NOC_FW_CPUPOOL_END>; /* NOC_FW_NONCOHERENT|NOC_FW_SPECIAL_REGION  NOC_FW_CPUPOOL_END */
			perm     = <NOC_FW_F_RW>;
		};
		rule_fw_dom_pcie10_4 { /*  27  in FW_HSIOL_Rules */
			op       = <NOC_FW_OP_ADD>;
			sai      = <SAI_IA_PCI_2_VAL>;
			base     = <NOC_FW_SPECIAL_REGION  NOC_FW_DDR_GENERIC_RW_START>;
			end      = <NOC_FW_SPECIAL_REGION  NOC_FW_DDR_GENERIC_RW_END>;
			perm     = <NOC_FW_F_RW>;
		};
		rule_fw_dom_pcie10_5 { /*  28  in FW_HSIOL_Rules */
			op       = <NOC_FW_OP_ADD>;
			sai      = <SAI_IA_PCI_2_VAL>;
			base     = <0xA0000000 NOC_FW_DDR_GENERIC_RW_START>; /* NOC_FW_NONCOHERENT|NOC_FW_SPECIAL_REGION  NOC_FW_DDR_GENERIC_RW_START */
			end      = <0xA0000000 NOC_FW_DDR_GENERIC_RW_END>; /* NOC_FW_NONCOHERENT|NOC_FW_SPECIAL_REGION  NOC_FW_DDR_GENERIC_RW_END */
			perm     = <NOC_FW_F_RW>;
		};
		rule_fw_dom_pcie10_6 { /*  30  in FW_HSIOL_Rules */
			op       = <NOC_FW_OP_ADD>;
			sai      = <SAI_IA_PCI_2_VAL>;
			base     = <0x0  0xFEE00000>;
			end      = <0x0  0xFEEFFFFF>;
			perm     = <NOC_FW_F_RW>;
		};
		};
		group_pcie10_deferred {
		rule_pcie10_deferred_1 { /*  23  in FW_HSIOL_Rules */
			op       = <NOC_FW_OP_ADD>;
			sai      = <SAI_IA_PCI_2_VAL>;
			base     = <NOC_FW_SPECIAL_REGION_DYN  NOC_FW_DYN_PCIE10_CQM_DCEQ_PORT_START>;
			end      = <NOC_FW_SPECIAL_REGION_DYN  NOC_FW_DYN_PCIE10_CQM_DCEQ_PORT_END>;
			perm     = <NOC_FW_F_RW>;
			deferred;
		};
		rule_pcie10_deferred_2 { /*  24  in FW_HSIOL_Rules */
			op       = <NOC_FW_OP_ADD>;
			sai      = <SAI_IA_PCI_2_VAL>;
			base     = <NOC_FW_SPECIAL_REGION_DYN  NOC_FW_DYN_PCIE10_CQM_DCDQ_PORT_START>;
			end      = <NOC_FW_SPECIAL_REGION_DYN  NOC_FW_DYN_PCIE10_CQM_DCDQ_PORT_END>;
			perm     = <NOC_FW_F_RW>;
			deferred;
		};
		rule_pcie10_deferred_3 { /*  25  in FW_HSIOL_Rules */
			op       = <NOC_FW_OP_ADD>;
			sai      = <SAI_IA_PCI_2_VAL>;
			base     = <NOC_FW_SPECIAL_REGION_DYN  NOC_FW_DYN_PCIE10_QOS_START>;
			end      = <NOC_FW_SPECIAL_REGION_DYN  NOC_FW_DYN_PCIE10_QOS_END>;
			perm     = <NOC_FW_F_RW>;
			deferred;
		};
		rule_pcie10_deferred_4 { /*  26  in FW_HSIOL_Rules */
			op       = <NOC_FW_OP_ADD>;
			sai      = <SAI_IA_PCI_2_VAL>;
			base     = <NOC_FW_SPECIAL_REGION_DYN  NOC_FW_DYN_PCIE10_BM_START>;
			end      = <NOC_FW_SPECIAL_REGION_DYN  NOC_FW_DYN_PCIE10_BM_END>;
			perm     = <NOC_FW_F_RW>;
			deferred;
		};
		rule_pcie10_deferred_5 { /*  62  in FW_PERI_Rules */
			op       = <NOC_FW_OP_ADD>;
			sai      = <SAI_IA_DEQ_VAL>;
			base     = <NOC_FW_SPECIAL_REGION_DYN  NOC_FW_DYN_PCIE10_PERI_UMT_START>;
			end      = <NOC_FW_SPECIAL_REGION_DYN  NOC_FW_DYN_PCIE10_PERI_UMT_END>;
			perm     = <NOC_FW_F_W>;
			deferred;
		};
		rule_pcie10_deferred_6 { /*  80  in FW_PERI_Rules */
			op       = <NOC_FW_OP_ADD>;
			sai      = <SAI_IA_ARCVPN_VAL>;
			base     = <NOC_FW_SPECIAL_REGION_DYN  NOC_FW_DYN_PCIE10_PERI_UMT_START>;
			end      = <NOC_FW_SPECIAL_REGION_DYN  NOC_FW_DYN_PCIE10_PERI_UMT_END>;
			perm     = <NOC_FW_F_W>;
			deferred;
		};
		};
	};
	fw_dom_pcie11:fw_dom_pcie11 {
		#firewall-domain-cells = <0>;
		sai = <SAI_IA_PCI_3_VAL>;
		group_fw_dom_pcie11 {
		rule_fw_dom_pcie11_1 { /*  31  in FW_HSIOL_Rules */
			op       = <NOC_FW_OP_ADD>;
			sai      = <SAI_IA_PCI_3_VAL>;
			base     = <0xA0000000 NOC_FW_SYSPOOL_START>; /* NOC_FW_NONCOHERENT|NOC_FW_SPECIAL_REGION  NOC_FW_SYSPOOL_START */
			end      = <0xA0000000 NOC_FW_SYSPOOL_END>; /* NOC_FW_NONCOHERENT|NOC_FW_SPECIAL_REGION  NOC_FW_SYSPOOL_END */
			perm     = <NOC_FW_F_RW>;
		};
		rule_fw_dom_pcie11_2 { /*  34  in FW_HSIOL_Rules */
			op       = <NOC_FW_OP_ADD>;
			sai      = <SAI_IA_PCI_3_VAL>;
			base     = <NOC_FW_SPECIAL_REGION_DYN  NOC_FW_DYN_PCIE11_BM_START>;
			end      = <NOC_FW_SPECIAL_REGION_DYN  NOC_FW_DYN_PCIE11_BM_END>;
			perm     = <NOC_FW_F_RW>;
		};
		rule_fw_dom_pcie11_3 { /*  35  in FW_HSIOL_Rules */
			op       = <NOC_FW_OP_ADD>;
			sai      = <SAI_IA_PCI_3_VAL>;
			base     = <NOC_FW_SPECIAL_REGION  NOC_FW_DDR_GENERIC_RW_START>;
			end      = <NOC_FW_SPECIAL_REGION  NOC_FW_DDR_GENERIC_RW_END>;
			perm     = <NOC_FW_F_RW>;
		};
		rule_fw_dom_pcie11_4 { /*  36  in FW_HSIOL_Rules */
			op       = <NOC_FW_OP_ADD>;
			sai      = <SAI_IA_PCI_3_VAL>;
			base     = <0xA0000000 NOC_FW_DDR_GENERIC_RW_START>; /* NOC_FW_NONCOHERENT|NOC_FW_SPECIAL_REGION  NOC_FW_DDR_GENERIC_RW_START */
			end      = <0xA0000000 NOC_FW_DDR_GENERIC_RW_END>; /* NOC_FW_NONCOHERENT|NOC_FW_SPECIAL_REGION  NOC_FW_DDR_GENERIC_RW_END */
			perm     = <NOC_FW_F_RW>;
		};
		rule_fw_dom_pcie11_5 { /*  38  in FW_HSIOL_Rules */
			op       = <NOC_FW_OP_ADD>;
			sai      = <SAI_IA_PCI_3_VAL>;
			base     = <0x0  0xFEE00000>;
			end      = <0x0  0xFEEFFFFF>;
			perm     = <NOC_FW_F_RW>;
		};
		};
		group_pcie11_deferred {
		rule_pcie11_deferred_1 { /*  32  in FW_HSIOL_Rules */
			op       = <NOC_FW_OP_ADD>;
			sai      = <SAI_IA_PCI_3_VAL>;
			base     = <NOC_FW_SPECIAL_REGION_DYN  NOC_FW_DYN_PCIE11_CQM_DCEQ_PORT_START>;
			end      = <NOC_FW_SPECIAL_REGION_DYN  NOC_FW_DYN_PCIE11_CQM_DCEQ_PORT_END>;
			perm     = <NOC_FW_F_RW>;
			deferred;
		};
		rule_pcie11_deferred_2 { /*  33  in FW_HSIOL_Rules */
			op       = <NOC_FW_OP_ADD>;
			sai      = <SAI_IA_PCI_3_VAL>;
			base     = <NOC_FW_SPECIAL_REGION_DYN  NOC_FW_DYN_PCIE11_CQM_DCDQ_PORT_START>;
			end      = <NOC_FW_SPECIAL_REGION_DYN  NOC_FW_DYN_PCIE11_CQM_DCDQ_PORT_END>;
			perm     = <NOC_FW_F_RW>;
			deferred;
		};
		rule_pcie11_deferred_3 { /*  63  in FW_PERI_Rules */
			op       = <NOC_FW_OP_ADD>;
			sai      = <SAI_IA_DEQ_VAL>;
			base     = <NOC_FW_SPECIAL_REGION_DYN  NOC_FW_DYN_PCIE11_PERI_UMT_START>;
			end      = <NOC_FW_SPECIAL_REGION_DYN  NOC_FW_DYN_PCIE11_PERI_UMT_END>;
			perm     = <NOC_FW_F_W>;
			deferred;
		};
		rule_pcie11_deferred_4 { /*  81  in FW_PERI_Rules */
			op       = <NOC_FW_OP_ADD>;
			sai      = <SAI_IA_ARCVPN_VAL>;
			base     = <NOC_FW_SPECIAL_REGION_DYN  NOC_FW_DYN_PCIE11_PERI_UMT_START>;
			end      = <NOC_FW_SPECIAL_REGION_DYN  NOC_FW_DYN_PCIE11_PERI_UMT_END>;
			perm     = <NOC_FW_F_W>;
			deferred;
		};
		};
	};
	fw_dom_pcie40:fw_dom_pcie40 {
		#firewall-domain-cells = <0>;
		sai = <SAI_IA_PCI_4_VAL>;
		group_fw_dom_pcie40 {
		rule_fw_dom_pcie40_1 { /*  4  in FW_HSIOR_Rules */
			op       = <NOC_FW_OP_ADD>;
			sai      = <SAI_IA_PCI_4_VAL>;
			base     = <0xA0000000 NOC_FW_SYSPOOL_START>; /* NOC_FW_NONCOHERENT|NOC_FW_SPECIAL_REGION  NOC_FW_SYSPOOL_START */
			end      = <0xA0000000 NOC_FW_SYSPOOL_END>; /* NOC_FW_NONCOHERENT|NOC_FW_SPECIAL_REGION  NOC_FW_SYSPOOL_END */
			perm     = <NOC_FW_F_RW>;
		};
		rule_fw_dom_pcie40_2 { /*  8  in FW_HSIOR_Rules */
			op       = <NOC_FW_OP_ADD>;
			sai      = <SAI_IA_PCI_4_VAL>;
			base     = <NOC_FW_SPECIAL_REGION  NOC_FW_DDR_GENERIC_RW_START>;
			end      = <NOC_FW_SPECIAL_REGION  NOC_FW_DDR_GENERIC_RW_END>;
			perm     = <NOC_FW_F_RW>;
		};
		rule_fw_dom_pcie40_3 { /*  9  in FW_HSIOR_Rules */
			op       = <NOC_FW_OP_ADD>;
			sai      = <SAI_IA_PCI_4_VAL>;
			base     = <0xA0000000 NOC_FW_DDR_GENERIC_RW_START>; /* NOC_FW_NONCOHERENT|NOC_FW_SPECIAL_REGION  NOC_FW_DDR_GENERIC_RW_START */
			end      = <0xA0000000 NOC_FW_DDR_GENERIC_RW_END>; /* NOC_FW_NONCOHERENT|NOC_FW_SPECIAL_REGION  NOC_FW_DDR_GENERIC_RW_END */
			perm     = <NOC_FW_F_RW>;
		};
		rule_fw_dom_pcie40_4 { /*  11  in FW_HSIOR_Rules */
			op       = <NOC_FW_OP_ADD>;
			sai      = <SAI_IA_PCI_4_VAL>;
			base     = <0x0  0xFEE00000>;
			end      = <0x0  0xFEEFFFFF>;
			perm     = <NOC_FW_F_RW>;
		};
		};
		group_pcie40_deferred {
		rule_pcie40_deferred_1 { /*  5  in FW_HSIOR_Rules */
			op       = <NOC_FW_OP_ADD>;
			sai      = <SAI_IA_PCI_4_VAL>;
			base     = <NOC_FW_SPECIAL_REGION_DYN  NOC_FW_DYN_PCIE40_CQM_DCEQ_PORT_START>;
			end      = <NOC_FW_SPECIAL_REGION_DYN  NOC_FW_DYN_PCIE40_CQM_DCEQ_PORT_END>;
			perm     = <NOC_FW_F_RW>;
			deferred;
		};
		rule_pcie40_deferred_2 { /*  6  in FW_HSIOR_Rules */
			op       = <NOC_FW_OP_ADD>;
			sai      = <SAI_IA_PCI_4_VAL>;
			base     = <NOC_FW_SPECIAL_REGION_DYN  NOC_FW_DYN_PCIE40_CQM_DCDQ_PORT_START>;
			end      = <NOC_FW_SPECIAL_REGION_DYN  NOC_FW_DYN_PCIE40_CQM_DCDQ_PORT_END>;
			perm     = <NOC_FW_F_RW>;
			deferred;
		};
		rule_pcie40_deferred_3 { /*  7  in FW_HSIOR_Rules */
			op       = <NOC_FW_OP_ADD>;
			sai      = <SAI_IA_PCI_4_VAL>;
			base     = <NOC_FW_SPECIAL_REGION_DYN  NOC_FW_DYN_PCIE40_BM_START>;
			end      = <NOC_FW_SPECIAL_REGION_DYN  NOC_FW_DYN_PCIE40_BM_END>;
			perm     = <NOC_FW_F_RW>;
			deferred;
		};
		rule_pcie40_deferred_4 { /*  68  in FW_PERI_Rules */
			op       = <NOC_FW_OP_ADD>;
			sai      = <SAI_IA_DEQ_VAL>;
			base     = <NOC_FW_SPECIAL_REGION_DYN  NOC_FW_DYN_PCIE40_PERI_UMT_START>;
			end      = <NOC_FW_SPECIAL_REGION_DYN  NOC_FW_DYN_PCIE40_PERI_UMT_END>;
			perm     = <NOC_FW_F_W>;
			deferred;
		};
		rule_pcie40_deferred_5 { /*  86  in FW_PERI_Rules */
			op       = <NOC_FW_OP_ADD>;
			sai      = <SAI_IA_ARCVPN_VAL>;
			base     = <NOC_FW_SPECIAL_REGION_DYN  NOC_FW_DYN_PCIE40_PERI_UMT_START>;
			end      = <NOC_FW_SPECIAL_REGION_DYN  NOC_FW_DYN_PCIE40_PERI_UMT_END>;
			perm     = <NOC_FW_F_W>;
			deferred;
		};
		};
	};
	fw_dom_pcie41:fw_dom_pcie41 {
		#firewall-domain-cells = <0>;
		sai = <SAI_IA_PCI_5_VAL>;
		group_fw_dom_pcie41 {
		rule_fw_dom_pcie41_1 { /*  12  in FW_HSIOR_Rules */
			op       = <NOC_FW_OP_ADD>;
			sai      = <SAI_IA_PCI_5_VAL>;
			base     = <0xA0000000 NOC_FW_SYSPOOL_START>; /* NOC_FW_NONCOHERENT|NOC_FW_SPECIAL_REGION  NOC_FW_SYSPOOL_START */
			end      = <0xA0000000 NOC_FW_SYSPOOL_END>; /* NOC_FW_NONCOHERENT|NOC_FW_SPECIAL_REGION  NOC_FW_SYSPOOL_END */
			perm     = <NOC_FW_F_RW>;
		};
		rule_fw_dom_pcie41_2 { /*  16  in FW_HSIOR_Rules */
			op       = <NOC_FW_OP_ADD>;
			sai      = <SAI_IA_PCI_5_VAL>;
			base     = <NOC_FW_SPECIAL_REGION  NOC_FW_DDR_GENERIC_RW_START>;
			end      = <NOC_FW_SPECIAL_REGION  NOC_FW_DDR_GENERIC_RW_END>;
			perm     = <NOC_FW_F_RW>;
		};
		rule_fw_dom_pcie41_3 { /*  17  in FW_HSIOR_Rules */
			op       = <NOC_FW_OP_ADD>;
			sai      = <SAI_IA_PCI_5_VAL>;
			base     = <0xA0000000 NOC_FW_DDR_GENERIC_RW_START>; /* NOC_FW_NONCOHERENT|NOC_FW_SPECIAL_REGION  NOC_FW_DDR_GENERIC_RW_START */
			end      = <0xA0000000 NOC_FW_DDR_GENERIC_RW_END>; /* NOC_FW_NONCOHERENT|NOC_FW_SPECIAL_REGION  NOC_FW_DDR_GENERIC_RW_END */
			perm     = <NOC_FW_F_RW>;
		};
		rule_fw_dom_pcie41_4 { /*  19  in FW_HSIOR_Rules */
			op       = <NOC_FW_OP_ADD>;
			sai      = <SAI_IA_PCI_5_VAL>;
			base     = <0x0  0xFEE00000>;
			end      = <0x0  0xFEEFFFFF>;
			perm     = <NOC_FW_F_RW>;
		};
		};
		group_pcie41_deferred {
		rule_pcie41_deferred_1 { /*  13  in FW_HSIOR_Rules */
			op       = <NOC_FW_OP_ADD>;
			sai      = <SAI_IA_PCI_5_VAL>;
			base     = <NOC_FW_SPECIAL_REGION_DYN  NOC_FW_DYN_PCIE41_CQM_DCEQ_PORT_START>;
			end      = <NOC_FW_SPECIAL_REGION_DYN  NOC_FW_DYN_PCIE41_CQM_DCEQ_PORT_END>;
			perm     = <NOC_FW_F_RW>;
			deferred;
		};
		rule_pcie41_deferred_2 { /*  14  in FW_HSIOR_Rules */
			op       = <NOC_FW_OP_ADD>;
			sai      = <SAI_IA_PCI_5_VAL>;
			base     = <NOC_FW_SPECIAL_REGION_DYN  NOC_FW_DYN_PCIE41_CQM_DCDQ_PORT_START>;
			end      = <NOC_FW_SPECIAL_REGION_DYN  NOC_FW_DYN_PCIE41_CQM_DCDQ_PORT_END>;
			perm     = <NOC_FW_F_RW>;
			deferred;
		};
		rule_pcie41_deferred_3 { /*  15  in FW_HSIOR_Rules */
			op       = <NOC_FW_OP_ADD>;
			sai      = <SAI_IA_PCI_5_VAL>;
			base     = <NOC_FW_SPECIAL_REGION_DYN  NOC_FW_DYN_PCIE41_BM_START>;
			end      = <NOC_FW_SPECIAL_REGION_DYN  NOC_FW_DYN_PCIE41_BM_END>;
			perm     = <NOC_FW_F_RW>;
			deferred;
		};
		rule_pcie41_deferred_4 { /*  69  in FW_PERI_Rules */
			op       = <NOC_FW_OP_ADD>;
			sai      = <SAI_IA_DEQ_VAL>;
			base     = <NOC_FW_SPECIAL_REGION_DYN  NOC_FW_DYN_PCIE41_PERI_UMT_START>;
			end      = <NOC_FW_SPECIAL_REGION_DYN  NOC_FW_DYN_PCIE41_PERI_UMT_END>;
			perm     = <NOC_FW_F_W>;
			deferred;
		};
		rule_pcie41_deferred_5 { /*  87  in FW_PERI_Rules */
			op       = <NOC_FW_OP_ADD>;
			sai      = <SAI_IA_ARCVPN_VAL>;
			base     = <NOC_FW_SPECIAL_REGION_DYN  NOC_FW_DYN_PCIE41_PERI_UMT_START>;
			end      = <NOC_FW_SPECIAL_REGION_DYN  NOC_FW_DYN_PCIE41_PERI_UMT_END>;
			perm     = <NOC_FW_F_W>;
			deferred;
		};
		};
	};
	fw_dom_pcie20:fw_dom_pcie20 {
		#firewall-domain-cells = <0>;
		sai = <SAI_IA_PCI_6_VAL>;
		group_fw_dom_pcie20 {
		rule_fw_dom_pcie20_1 { /*  20  in FW_HSIOR_Rules */
			op       = <NOC_FW_OP_ADD>;
			sai      = <SAI_IA_PCI_6_VAL>;
			base     = <0xA0000000 NOC_FW_SYSPOOL_START>; /* NOC_FW_NONCOHERENT|NOC_FW_SPECIAL_REGION  NOC_FW_SYSPOOL_START */
			end      = <0xA0000000 NOC_FW_SYSPOOL_END>; /* NOC_FW_NONCOHERENT|NOC_FW_SPECIAL_REGION  NOC_FW_SYSPOOL_END */
			perm     = <NOC_FW_F_RW>;
		};
		rule_fw_dom_pcie20_2 { /*  21  in FW_HSIOR_Rules */
			op       = <NOC_FW_OP_ADD>;
			sai      = <SAI_IA_PCI_6_VAL>;
			base     = <NOC_FW_SPECIAL_REGION  NOC_FW_CPUPOOL_START>;
			end      = <NOC_FW_SPECIAL_REGION  NOC_FW_CPUPOOL_END>;
			perm     = <NOC_FW_F_RW>;
		};
		rule_fw_dom_pcie20_3 { /*  22  in FW_HSIOR_Rules */
			op       = <NOC_FW_OP_ADD>;
			sai      = <SAI_IA_PCI_6_VAL>;
			base     = <0xA0000000 NOC_FW_CPUPOOL_START>; /* NOC_FW_NONCOHERENT|NOC_FW_SPECIAL_REGION  NOC_FW_CPUPOOL_START */
			end      = <0xA0000000 NOC_FW_CPUPOOL_END>; /* NOC_FW_NONCOHERENT|NOC_FW_SPECIAL_REGION  NOC_FW_CPUPOOL_END */
			perm     = <NOC_FW_F_RW>;
		};
		rule_fw_dom_pcie20_4 { /*  27  in FW_HSIOR_Rules */
			op       = <NOC_FW_OP_ADD>;
			sai      = <SAI_IA_PCI_6_VAL>;
			base     = <NOC_FW_SPECIAL_REGION  NOC_FW_DDR_GENERIC_RW_START>;
			end      = <NOC_FW_SPECIAL_REGION  NOC_FW_DDR_GENERIC_RW_END>;
			perm     = <NOC_FW_F_RW>;
		};
		rule_fw_dom_pcie20_5 { /*  28  in FW_HSIOR_Rules */
			op       = <NOC_FW_OP_ADD>;
			sai      = <SAI_IA_PCI_6_VAL>;
			base     = <0xA0000000 NOC_FW_DDR_GENERIC_RW_START>; /* NOC_FW_NONCOHERENT|NOC_FW_SPECIAL_REGION  NOC_FW_DDR_GENERIC_RW_START */
			end      = <0xA0000000 NOC_FW_DDR_GENERIC_RW_END>; /* NOC_FW_NONCOHERENT|NOC_FW_SPECIAL_REGION  NOC_FW_DDR_GENERIC_RW_END */
			perm     = <NOC_FW_F_RW>;
		};
		rule_fw_dom_pcie20_6 { /*  30  in FW_HSIOR_Rules */
			op       = <NOC_FW_OP_ADD>;
			sai      = <SAI_IA_PCI_6_VAL>;
			base     = <0x0  0xFEE00000>;
			end      = <0x0  0xFEEFFFFF>;
			perm     = <NOC_FW_F_RW>;
		};
		};
		group_pcie20_deferred {
		rule_pcie20_deferred_1 { /*  23  in FW_HSIOR_Rules */
			op       = <NOC_FW_OP_ADD>;
			sai      = <SAI_IA_PCI_6_VAL>;
			base     = <NOC_FW_SPECIAL_REGION_DYN  NOC_FW_DYN_PCIE20_CQM_DCEQ_PORT_START>;
			end      = <NOC_FW_SPECIAL_REGION_DYN  NOC_FW_DYN_PCIE20_CQM_DCEQ_PORT_END>;
			perm     = <NOC_FW_F_RW>;
			deferred;
		};
		rule_pcie20_deferred_2 { /*  24  in FW_HSIOR_Rules */
			op       = <NOC_FW_OP_ADD>;
			sai      = <SAI_IA_PCI_6_VAL>;
			base     = <NOC_FW_SPECIAL_REGION_DYN  NOC_FW_DYN_PCIE20_CQM_DCDQ_PORT_START>;
			end      = <NOC_FW_SPECIAL_REGION_DYN  NOC_FW_DYN_PCIE20_CQM_DCDQ_PORT_END>;
			perm     = <NOC_FW_F_RW>;
			deferred;
		};
		rule_pcie20_deferred_3 { /*  25  in FW_HSIOR_Rules */
			op       = <NOC_FW_OP_ADD>;
			sai      = <SAI_IA_PCI_6_VAL>;
			base     = <NOC_FW_SPECIAL_REGION_DYN  NOC_FW_DYN_PCIE20_QOS_START>;
			end      = <NOC_FW_SPECIAL_REGION_DYN  NOC_FW_DYN_PCIE20_QOS_END>;
			perm     = <NOC_FW_F_RW>;
			deferred;
		};
		rule_pcie20_deferred_4 { /*  26  in FW_HSIOR_Rules */
			op       = <NOC_FW_OP_ADD>;
			sai      = <SAI_IA_PCI_6_VAL>;
			base     = <NOC_FW_SPECIAL_REGION_DYN  NOC_FW_DYN_PCIE20_BM_START>;
			end      = <NOC_FW_SPECIAL_REGION_DYN  NOC_FW_DYN_PCIE20_BM_END>;
			perm     = <NOC_FW_F_RW>;
			deferred;
		};
		rule_pcie20_deferred_5 { /*  66  in FW_PERI_Rules */
			op       = <NOC_FW_OP_ADD>;
			sai      = <SAI_IA_DEQ_VAL>;
			base     = <NOC_FW_SPECIAL_REGION_DYN  NOC_FW_DYN_PCIE20_PERI_UMT_START>;
			end      = <NOC_FW_SPECIAL_REGION_DYN  NOC_FW_DYN_PCIE20_PERI_UMT_END>;
			perm     = <NOC_FW_F_W>;
			deferred;
		};
		rule_pcie20_deferred_6 { /*  84  in FW_PERI_Rules */
			op       = <NOC_FW_OP_ADD>;
			sai      = <SAI_IA_ARCVPN_VAL>;
			base     = <NOC_FW_SPECIAL_REGION_DYN  NOC_FW_DYN_PCIE20_PERI_UMT_START>;
			end      = <NOC_FW_SPECIAL_REGION_DYN  NOC_FW_DYN_PCIE20_PERI_UMT_END>;
			perm     = <NOC_FW_F_W>;
			deferred;
		};
		};
	};
	fw_dom_pcie21:fw_dom_pcie21 {
		#firewall-domain-cells = <0>;
		sai = <SAI_IA_PCI_7_VAL>;
		group_fw_dom_pcie21 {
		rule_fw_dom_pcie21_1 { /*  31  in FW_HSIOR_Rules */
			op       = <NOC_FW_OP_ADD>;
			sai      = <SAI_IA_PCI_7_VAL>;
			base     = <0xA0000000 NOC_FW_SYSPOOL_START>; /* NOC_FW_NONCOHERENT|NOC_FW_SPECIAL_REGION  NOC_FW_SYSPOOL_START */
			end      = <0xA0000000 NOC_FW_SYSPOOL_END>; /* NOC_FW_NONCOHERENT|NOC_FW_SPECIAL_REGION  NOC_FW_SYSPOOL_END */
			perm     = <NOC_FW_F_RW>;
		};
		rule_fw_dom_pcie21_2 { /*  34  in FW_HSIOR_Rules */
			op       = <NOC_FW_OP_ADD>;
			sai      = <SAI_IA_PCI_7_VAL>;
			base     = <NOC_FW_SPECIAL_REGION_DYN  NOC_FW_DYN_PCIE21_BM_START>;
			end      = <NOC_FW_SPECIAL_REGION_DYN  NOC_FW_DYN_PCIE21_BM_END>;
			perm     = <NOC_FW_F_RW>;
		};
		rule_fw_dom_pcie21_3 { /*  35  in FW_HSIOR_Rules */
			op       = <NOC_FW_OP_ADD>;
			sai      = <SAI_IA_PCI_7_VAL>;
			base     = <NOC_FW_SPECIAL_REGION  NOC_FW_DDR_GENERIC_RW_START>;
			end      = <NOC_FW_SPECIAL_REGION  NOC_FW_DDR_GENERIC_RW_END>;
			perm     = <NOC_FW_F_RW>;
		};
		rule_fw_dom_pcie21_4 { /*  36  in FW_HSIOR_Rules */
			op       = <NOC_FW_OP_ADD>;
			sai      = <SAI_IA_PCI_7_VAL>;
			base     = <0xA0000000 NOC_FW_DDR_GENERIC_RW_START>; /* NOC_FW_NONCOHERENT|NOC_FW_SPECIAL_REGION  NOC_FW_DDR_GENERIC_RW_START */
			end      = <0xA0000000 NOC_FW_DDR_GENERIC_RW_END>; /* NOC_FW_NONCOHERENT|NOC_FW_SPECIAL_REGION  NOC_FW_DDR_GENERIC_RW_END */
			perm     = <NOC_FW_F_RW>;
		};
		rule_fw_dom_pcie21_5 { /*  38  in FW_HSIOR_Rules */
			op       = <NOC_FW_OP_ADD>;
			sai      = <SAI_IA_PCI_7_VAL>;
			base     = <0x0  0xFEE00000>;
			end      = <0x0  0xFEEFFFFF>;
			perm     = <NOC_FW_F_RW>;
		};
		};
		group_pcie21_deferred {
		rule_pcie21_deferred_1 { /*  32  in FW_HSIOR_Rules */
			op       = <NOC_FW_OP_ADD>;
			sai      = <SAI_IA_PCI_7_VAL>;
			base     = <NOC_FW_SPECIAL_REGION_DYN  NOC_FW_DYN_PCIE21_CQM_DCEQ_PORT_START>;
			end      = <NOC_FW_SPECIAL_REGION_DYN  NOC_FW_DYN_PCIE21_CQM_DCEQ_PORT_END>;
			perm     = <NOC_FW_F_RW>;
			deferred;
		};
		rule_pcie21_deferred_2 { /*  33  in FW_HSIOR_Rules */
			op       = <NOC_FW_OP_ADD>;
			sai      = <SAI_IA_PCI_7_VAL>;
			base     = <NOC_FW_SPECIAL_REGION_DYN  NOC_FW_DYN_PCIE21_CQM_DCDQ_PORT_START>;
			end      = <NOC_FW_SPECIAL_REGION_DYN  NOC_FW_DYN_PCIE21_CQM_DCDQ_PORT_END>;
			perm     = <NOC_FW_F_RW>;
			deferred;
		};
		rule_pcie21_deferred_3 { /*  67  in FW_PERI_Rules */
			op       = <NOC_FW_OP_ADD>;
			sai      = <SAI_IA_DEQ_VAL>;
			base     = <NOC_FW_SPECIAL_REGION_DYN  NOC_FW_DYN_PCIE21_PERI_UMT_START>;
			end      = <NOC_FW_SPECIAL_REGION_DYN  NOC_FW_DYN_PCIE21_PERI_UMT_END>;
			perm     = <NOC_FW_F_W>;
			deferred;
		};
		rule_pcie21_deferred_4 { /*  85  in FW_PERI_Rules */
			op       = <NOC_FW_OP_ADD>;
			sai      = <SAI_IA_ARCVPN_VAL>;
			base     = <NOC_FW_SPECIAL_REGION_DYN  NOC_FW_DYN_PCIE21_PERI_UMT_START>;
			end      = <NOC_FW_SPECIAL_REGION_DYN  NOC_FW_DYN_PCIE21_PERI_UMT_END>;
			perm     = <NOC_FW_F_W>;
			deferred;
		};
		};
	};

#ifndef LGMC_SOC
	fw_dom_usb0:fw_dom_usb0 {
		#firewall-domain-cells = <0>;
		sai = <SAI_IA_USB_0_VAL>;
		group_fw_dom_usb0 {
		rule_fw_dom_usb0_1 { /*  31  in FW_DDR_Rules */
			op       = <NOC_FW_OP_ADD>;
			sai      = <SAI_IA_USB_0_VAL>;
			base     = <NOC_FW_SPECIAL_REGION  NOC_FW_DDR_GENERIC_RW_START>;
			end      = <NOC_FW_SPECIAL_REGION  NOC_FW_DDR_GENERIC_RW_END>;
			perm     = <NOC_FW_F_RW>;
		};
		};
	};
#endif

	fw_dom_usb1:fw_dom_usb1 {
		#firewall-domain-cells = <0>;
		sai = <SAI_IA_USB_1_VAL>;
		group_fw_dom_usb1 {
		rule_fw_dom_usb1_1 { /*  32  in FW_DDR_Rules */
			op       = <NOC_FW_OP_ADD>;
			sai      = <SAI_IA_USB_1_VAL>;
			base     = <NOC_FW_SPECIAL_REGION  NOC_FW_DDR_GENERIC_RW_START>;
			end      = <NOC_FW_SPECIAL_REGION  NOC_FW_DDR_GENERIC_RW_END>;
			perm     = <NOC_FW_F_RW>;
		};
		};
	};
	fw_dom_tep:fw_dom_tep {
		#firewall-domain-cells = <0>;
		sai = <SAI_IA_TEP_VAL>;
		group_fw_dom_tep {
		};
	};

#ifndef LGMC_SOC
	fw_dom_sata2:fw_dom_sata2 {
		#firewall-domain-cells = <0>;
		sai = <SAI_IA_SATA_2_VAL>;
		group_fw_dom_sata2 {
		rule_fw_dom_sata2_1 { /*  39  in FW_HSIOR_Rules */
			op       = <NOC_FW_OP_ADD>;
			sai      = <SAI_IA_SATA_2_VAL>;
			base     = <NOC_FW_SPECIAL_REGION  NOC_FW_DDR_GENERIC_RW_START>;
			end      = <NOC_FW_SPECIAL_REGION  NOC_FW_DDR_GENERIC_RW_END>;
			perm     = <NOC_FW_F_RW>;
		};
		};
	};
	fw_dom_sata3:fw_dom_sata3 {
		#firewall-domain-cells = <0>;
		sai = <SAI_IA_SATA_3_VAL>;
		group_fw_dom_sata3 {
		rule_fw_dom_sata3_1 { /*  40  in FW_HSIOR_Rules */
			op       = <NOC_FW_OP_ADD>;
			sai      = <SAI_IA_SATA_3_VAL>;
			base     = <NOC_FW_SPECIAL_REGION  NOC_FW_DDR_GENERIC_RW_START>;
			end      = <NOC_FW_SPECIAL_REGION  NOC_FW_DDR_GENERIC_RW_END>;
			perm     = <NOC_FW_F_RW>;
		};
		};
	};
#endif

	fw_dom_peridma0:fw_dom_peridma0 {
		#firewall-domain-cells = <0>;
		sai = <SAI_IA_DMA0_VAL>;
		group_fw_dom_peridma0 {
		rule_fw_dom_peridma0_1 { /*  34  in FW_PERI_Rules */
			op       = <NOC_FW_OP_ADD>;
			sai      = <SAI_IA_DMA0_VAL>;
			base     = <0x0  0xE0800000>;
			end      = <0x0  0xE08FFFFF>;
			perm     = <NOC_FW_F_RW>;
		};
		rule_fw_dom_peridma0_2 { /*  35  in FW_PERI_Rules */
			op       = <NOC_FW_OP_ADD>;
			sai      = <SAI_IA_DMA0_VAL>;
			base     = <0x0  0xE0900000>;
			end      = <0x0  0xE09FFFFF>;
			perm     = <NOC_FW_F_RW>;
		};
		rule_fw_dom_peridma0_3 { /*  36  in FW_PERI_Rules */
			op       = <NOC_FW_OP_ADD>;
			sai      = <SAI_IA_DMA0_VAL>;
			base     = <0x0  0xE1D00000>;
			end      = <0x0  0xE1DFFFFF>;
			perm     = <NOC_FW_F_RW>;
		};
		rule_fw_dom_peridma0_4 { /*  37  in FW_PERI_Rules */
			op       = <NOC_FW_OP_ADD>;
			sai      = <SAI_IA_DMA0_VAL>;
			base     = <0x0  0xE1E00000>;
			end      = <0x0  0xE1EFFFFF>;
			perm     = <NOC_FW_F_RW>;
		};
		rule_fw_dom_peridma0_5 { /*  38  in FW_PERI_Rules */
			op       = <NOC_FW_OP_ADD>;
			sai      = <SAI_IA_DMA0_VAL>;
			base     = <0x0  0xE2400000>;
			end      = <0x0  0xE2400FFF>;
			perm     = <NOC_FW_F_RW>;
		};
		rule_fw_dom_peridma0_6 { /*  39  in FW_PERI_Rules */
			op       = <NOC_FW_OP_ADD>;
			sai      = <SAI_IA_DMA0_VAL>;
			base     = <0x0  0xE2200000>;
			end      = <0x0  0xE2200FFF>;
			perm     = <NOC_FW_F_RW>;
		};
		rule_fw_dom_peridma0_7 { /*  40  in FW_PERI_Rules */
			op       = <NOC_FW_OP_ADD>;
			sai      = <SAI_IA_DMA0_VAL>;
			base     = <0x0  0xE2300000>;
			end      = <0x0  0xE2300FFF>;
			perm     = <NOC_FW_F_RW>;
		};
		};
	};
	fw_dom_spidbg:fw_dom_spidbg {
		#firewall-domain-cells = <0>;
		sai = <SAI_IA_DBGSPI_VAL>;
		group_fw_dom_spidbg {
		};
	};
	fw_dom_toe:fw_dom_toe {
		#firewall-domain-cells = <0>;
		sai = <SAI_IA_TOE_VAL>;
		group_fw_dom_toe {
		rule_fw_dom_toe_1 { /*  42  in FW_PERI_Rules */
			op       = <NOC_FW_OP_ADD>;
			sai      = <SAI_IA_TOE_VAL>;
			base     = <0x0  0xE66C0000>;
			end      = <0x0  0xE6CFFFFF>;
			perm     = <NOC_FW_F_RW>;
		};
		rule_fw_dom_toe_2 { /*  7  in FW_SSB_Rules */
			op       = <NOC_FW_OP_ADD>;
			sai      = <SAI_IA_TOE_VAL>;
			base     = <0x0  0xECD00000>;
			end      = <0x0  0xECD7FFFF>;
			perm     = <NOC_FW_F_RW>;
		};
		rule_fw_dom_toe_3 { /*  35  in FW_DDR_Rules */
			op       = <NOC_FW_OP_ADD>;
			sai      = <SAI_IA_TOE_VAL>;
			base     = <NOC_FW_SPECIAL_REGION  NOC_FW_CPUPOOL_START>;
			end      = <NOC_FW_SPECIAL_REGION  NOC_FW_CPUPOOL_END>;
			perm     = <NOC_FW_F_RW>;
		};
		rule_fw_dom_toe_4 { /*  36  in FW_DDR_Rules */
			op       = <NOC_FW_OP_ADD>;
			sai      = <SAI_IA_TOE_VAL>;
			base     = <0xA0000000 NOC_FW_SYSPOOL_START>; /* NOC_FW_NONCOHERENT|NOC_FW_SPECIAL_REGION  NOC_FW_SYSPOOL_START */
			end      = <0xA0000000 NOC_FW_SYSPOOL_END>; /* NOC_FW_NONCOHERENT|NOC_FW_SPECIAL_REGION  NOC_FW_SYSPOOL_END */
			perm     = <NOC_FW_F_RW>;
		};
		rule_fw_dom_toe_5 { /*  38  in FW_DDR_Rules */
			op       = <NOC_FW_OP_ADD>;
			sai      = <SAI_IA_TOE_VAL>;
			base     = <0xA0000000 NOC_FW_DDR_GENERIC_RW_START>; /* NOC_FW_NONCOHERENT|NOC_FW_SPECIAL_REGION  NOC_FW_DDR_GENERIC_RW_START */
			end      = <0xA0000000 NOC_FW_DDR_GENERIC_RW_END>; /* NOC_FW_NONCOHERENT|NOC_FW_SPECIAL_REGION  NOC_FW_DDR_GENERIC_RW_END */
			perm     = <NOC_FW_F_RW>;
		};
		rule_fw_dom_toe_6 { /*  39  in FW_DDR_Rules */
			op       = <NOC_FW_OP_ADD>;
			sai      = <SAI_IA_TOE_VAL>;
			base     = <NOC_FW_SPECIAL_REGION  NOC_FW_DDR_GENERIC_RW_START>;
			end      = <NOC_FW_SPECIAL_REGION  NOC_FW_DDR_GENERIC_RW_END>;
			perm     = <NOC_FW_F_RW>;
		};
		};
		group_toe_deferred {
		rule_toe_deferred_1 { /*  37  in FW_DDR_Rules */
			op       = <NOC_FW_OP_ADD>;
			sai      = <SAI_IA_TOE_VAL>;
			base     = <NOC_FW_SPECIAL_REGION_DYN  NOC_FW_DYN_DDR_GATHERBUF_START>;
			end      = <NOC_FW_SPECIAL_REGION_DYN  NOC_FW_DYN_DDR_GATHERBUF_END>;
			perm     = <NOC_FW_F_RW>;
			deferred;
		};
		};
	};
	fw_dom_toedma:fw_dom_toedma {
		#firewall-domain-cells = <0>;
		sai = <SAI_IA_TOER_VAL>;
		group_fw_dom_toedma {
		rule_fw_dom_toedma_1 { /*  40  in FW_DDR_Rules */
			op       = <NOC_FW_OP_ADD>;
			sai      = <SAI_IA_TOER_VAL>;
			base     = <NOC_FW_SPECIAL_REGION  NOC_FW_DDR_GENERIC_RW_START>;
			end      = <NOC_FW_SPECIAL_REGION  NOC_FW_DDR_GENERIC_RW_END>;
			perm     = <NOC_FW_F_RW>;
		};
		rule_fw_dom_toedma_2 { /*  43  in FW_DDR_Rules */
			op       = <NOC_FW_OP_ADD>;
			sai      = <SAI_IA_TOER_VAL>;
			base     = <0xA0000000 NOC_FW_SYSPOOL_START>; /* NOC_FW_NONCOHERENT|NOC_FW_SPECIAL_REGION  NOC_FW_SYSPOOL_START */
			end      = <0xA0000000 NOC_FW_SYSPOOL_END>; /* NOC_FW_NONCOHERENT|NOC_FW_SPECIAL_REGION  NOC_FW_SYSPOOL_END */
			perm     = <NOC_FW_F_RW>;
		};
		rule_fw_dom_toedma_3 { /*  44  in FW_DDR_Rules */
			op       = <NOC_FW_OP_ADD>;
			sai      = <SAI_IA_TOER_VAL>;
			base     = <NOC_FW_SPECIAL_REGION  NOC_FW_CPUPOOL_START>;
			end      = <NOC_FW_SPECIAL_REGION  NOC_FW_CPUPOOL_END>;
			perm     = <NOC_FW_F_RW>;
		};
		};
	};
	fw_dom_socmsi:fw_dom_socmsi {
		#firewall-domain-cells = <0>;
		sai = <SAI_IA_SOCMSIGEN_VAL>;
		group_fw_dom_socmsi {
		};
	};
	fw_dom_mcpydma3:fw_dom_mcpydma3 {
		#firewall-domain-cells = <0>;
		sai = <SAI_IA_DMA3_VAL>;
		group_fw_dom_mcpydma3 {
		rule_fw_dom_mcpydma3_1 { /*  47  in FW_PERI_Rules */
			op       = <NOC_FW_OP_ADD>;
			sai      = <SAI_IA_DMA3_VAL>;
			base     = <0x0  0xE6040000>;
			end      = <0x0  0xE60474FF>;
			perm     = <NOC_FW_F_RW>;
		};
		rule_fw_dom_mcpydma3_2 { /*  45  in FW_DDR_Rules */
			op       = <NOC_FW_OP_ADD>;
			sai      = <SAI_IA_DMA3_VAL>;
			base     = <NOC_FW_SPECIAL_REGION  NOC_FW_DDR_GENERIC_RW_START>;
			end      = <NOC_FW_SPECIAL_REGION  NOC_FW_DDR_GENERIC_RW_END>;
			perm     = <NOC_FW_F_RW>;
		};
		rule_fw_dom_mcpydma3_3 { /*  46  in FW_DDR_Rules */
			op       = <NOC_FW_OP_ADD>;
			sai      = <SAI_IA_DMA3_VAL>;
			base     = <0xA0000000 NOC_FW_DDR_GENERIC_RW_START>; /* NOC_FW_NONCOHERENT|NOC_FW_SPECIAL_REGION  NOC_FW_DDR_GENERIC_RW_START */
			end      = <0xA0000000 NOC_FW_DDR_GENERIC_RW_END>; /* NOC_FW_NONCOHERENT|NOC_FW_SPECIAL_REGION  NOC_FW_DDR_GENERIC_RW_END */
			perm     = <NOC_FW_F_RW>;
		};
		};
	};
	fw_dom_voice:fw_dom_voice {
		#firewall-domain-cells = <0>;
		sai = <SAI_IA_VOICE_VAL>;
		group_fw_dom_voice {
		rule_fw_dom_voice_1 { /*  27  in FW_DDR_Rules */
			op       = <NOC_FW_OP_ADD>;
			sai      = <SAI_IA_VOICE_VAL>;
			base     = <0xC  0xC00000>;
			end      = <0xC  0xFFFFFF>;
			perm     = <NOC_FW_F_RW>;
		};
		};
		group_voice_deferred {
		rule_voice_deferred_1 { /*  48  in FW_PERI_Rules */
			op       = <NOC_FW_OP_ADD>;
			sai      = <SAI_IA_VOICE_VAL>;
			base     = <NOC_FW_SPECIAL_REGION_DYN  NOC_FW_DYN_VOICE_DQM_START>;
			end      = <NOC_FW_SPECIAL_REGION_DYN  NOC_FW_DYN_VOICE_DQM_END>;
			perm     = <NOC_FW_F_RW>;
			deferred;
		};
		rule_voice_deferred_2 { /*  49  in FW_PERI_Rules */
			op       = <NOC_FW_OP_ADD>;
			sai      = <SAI_IA_VOICE_VAL>;
			base     = <NOC_FW_SPECIAL_REGION_DYN  NOC_FW_DYN_VOICE_EQM_START>;
			end      = <NOC_FW_SPECIAL_REGION_DYN  NOC_FW_DYN_VOICE_EQM_END>;
			perm     = <NOC_FW_F_RW>;
			deferred;
		};
		rule_voice_deferred_3 { /*  6  in FW_ETHNoC_Rules */
			op       = <NOC_FW_OP_ADD>;
			sai      = <SAI_IA_DMAR_VAL>;
			target   = <&ssx_voice>;
			base     = <0x60000000 NOC_FW_DYN_VOICEPOOL_START>; /* NOC_FW_NONCOHERENT|NOC_FW_SPECIAL_REGION_DYN  NOC_FW_DYN_VOICEPOOL_START */
			end      = <0x60000000 NOC_FW_DYN_VOICEPOOL_END>; /* NOC_FW_NONCOHERENT|NOC_FW_SPECIAL_REGION_DYN  NOC_FW_DYN_VOICEPOOL_END */
			perm     = <NOC_FW_F_W>;
			deferred;
		};
		rule_voice_deferred_4 { /*  7  in FW_ETHNoC_Rules */
			op       = <NOC_FW_OP_ADD>;
			sai      = <SAI_IA_DMAT_VAL>;
			target   = <&ssx_voice>;
			base     = <0x60000000 NOC_FW_DYN_VOICEPOOL_START>; /* NOC_FW_NONCOHERENT|NOC_FW_SPECIAL_REGION_DYN  NOC_FW_DYN_VOICEPOOL_START */
			end      = <0x60000000 NOC_FW_DYN_VOICEPOOL_END>; /* NOC_FW_NONCOHERENT|NOC_FW_SPECIAL_REGION_DYN  NOC_FW_DYN_VOICEPOOL_END */
			perm     = <NOC_FW_F_R>;
			deferred;
		};
		rule_voice_deferred_5 { /*  16  in FW_DDR_Rules */
			op       = <NOC_FW_OP_MODIFY>;
			sai      = <SAI_IA_MEMAXI_VAL>;
			base     = <0x60000000 NOC_FW_DYN_VOICE_ATOM_RW_START>; /* NOC_FW_NONCOHERENT|NOC_FW_SPECIAL_REGION_DYN  NOC_FW_DYN_VOICE_ATOM_RW_START */
			end      = <0x60000000 NOC_FW_DYN_VOICE_ATOM_RW_END>; /* NOC_FW_NONCOHERENT|NOC_FW_SPECIAL_REGION_DYN  NOC_FW_DYN_VOICE_ATOM_RW_END */
			perm     = <NOC_FW_F_RW>;
			deferred;
		};
		rule_voice_deferred_6 { /*  18  in FW_DDR_Rules */
			op       = <NOC_FW_OP_ADD>;
			sai      = <SAI_IA_MEMAXI_VAL>;
			base     = <0x60000000 NOC_FW_DYN_VOICE_ATOM_RO_START>; /* NOC_FW_NONCOHERENT|NOC_FW_SPECIAL_REGION_DYN  NOC_FW_DYN_VOICE_ATOM_RO_START */
			end      = <0x60000000 NOC_FW_DYN_VOICE_ATOM_RO_END>; /* NOC_FW_NONCOHERENT|NOC_FW_SPECIAL_REGION_DYN  NOC_FW_DYN_VOICE_ATOM_RO_END */
			perm     = <NOC_FW_F_R>;
			deferred;
		};
		rule_voice_deferred_7 { /*  28  in FW_DDR_Rules */
			op       = <NOC_FW_OP_MODIFY_SPLIT>;
			sai      = <SAI_IA_VOICE_VAL>;
			base     = <0x60000000 NOC_FW_DYN_VOICE_C55_RO_START>; /* NOC_FW_NONCOHERENT|NOC_FW_SPECIAL_REGION_DYN  NOC_FW_DYN_VOICE_C55_RO_START */
			end      = <0x60000000 NOC_FW_DYN_VOICE_C55_RO_END>; /* NOC_FW_NONCOHERENT|NOC_FW_SPECIAL_REGION_DYN  NOC_FW_DYN_VOICE_C55_RO_END */
			perm     = <NOC_FW_F_R>;
			deferred;
		};
		rule_voice_deferred_8 { /*  29  in FW_DDR_Rules */
			op       = <NOC_FW_OP_ADD>;
			sai      = <SAI_IA_VOICE_VAL>;
			base     = <0x60000000 NOC_FW_DYN_VOICE_C55_RW_START>; /* NOC_FW_NONCOHERENT|NOC_FW_SPECIAL_REGION_DYN  NOC_FW_DYN_VOICE_C55_RW_START */
			end      = <0x60000000 NOC_FW_DYN_VOICE_C55_RW_END>; /* NOC_FW_NONCOHERENT|NOC_FW_SPECIAL_REGION_DYN  NOC_FW_DYN_VOICE_C55_RW_END */
			perm     = <NOC_FW_F_RW>;
			deferred;
		};
		rule_voice_deferred_9 { /*  52  in FW_DDR_Rules */
			op       = <NOC_FW_OP_ADD>;
			sai      = <SAI_IA_PP_VAL>;
			target   = <&ssx_voice>;
			base     = <0x60000000 NOC_FW_DYN_VOICEPOOL_START>; /* NOC_FW_NONCOHERENT|NOC_FW_SPECIAL_REGION_DYN  NOC_FW_DYN_VOICEPOOL_START */
			end      = <0x60000000 NOC_FW_DYN_VOICEPOOL_END>; /* NOC_FW_NONCOHERENT|NOC_FW_SPECIAL_REGION_DYN  NOC_FW_DYN_VOICEPOOL_END */
			perm     = <NOC_FW_F_RW>;
			deferred;
		};
		};
	};
	fw_dom_crypto:fw_dom_crypto {
		#firewall-domain-cells = <0>;
		sai = <SAI_IA_E197_VAL>;
		group_fw_dom_crypto {
		rule_fw_dom_crypto_1 { /*  52  in FW_PERI_Rules */
			op       = <NOC_FW_OP_ADD>;
			sai      = <SAI_IA_E197_VAL>;
			target   = <&vpn>;
			base     = <0x0  0xE7B01000>;
			end      = <0x0  0xE7B02FFF>;
			perm     = <NOC_FW_F_RW>;
		};
		rule_fw_dom_crypto_2 { /*  47  in FW_DDR_Rules */
			op       = <NOC_FW_OP_ADD>;
			sai      = <SAI_IA_E197_VAL>;
			base     = <NOC_FW_SPECIAL_REGION  NOC_FW_DDR_GENERIC_RW_START>;
			end      = <NOC_FW_SPECIAL_REGION  NOC_FW_DDR_GENERIC_RW_END>;
			perm     = <NOC_FW_F_RW>;
		};
		rule_fw_dom_crypto_3 { /*  48  in FW_DDR_Rules */
			op       = <NOC_FW_OP_ADD>;
			sai      = <SAI_IA_E197_VAL>;
			base     = <0xA0000000 NOC_FW_SYSPOOL_START>; /* NOC_FW_NONCOHERENT|NOC_FW_SPECIAL_REGION  NOC_FW_SYSPOOL_START */
			end      = <0xA0000000 NOC_FW_SYSPOOL_END>; /* NOC_FW_NONCOHERENT|NOC_FW_SPECIAL_REGION  NOC_FW_SYSPOOL_END */
			perm     = <NOC_FW_F_RW>;
		};
		};
	};
	fw_dom_sdxc:fw_dom_sdxc {
		#firewall-domain-cells = <0>;
		sai = <SAI_IA_SDXC_VAL>;
		group_fw_dom_sdxc {
		rule_fw_dom_sdxc_1 { /*  49  in FW_DDR_Rules */
			op       = <NOC_FW_OP_ADD>;
			sai      = <SAI_IA_SDXC_VAL>;
			base     = <NOC_FW_SPECIAL_REGION  NOC_FW_DDR_GENERIC_RW_START>;
			end      = <NOC_FW_SPECIAL_REGION  NOC_FW_DDR_GENERIC_RW_END>;
			perm     = <NOC_FW_F_RW>;
		};
		};
	};
	fw_dom_emmc:fw_dom_emmc {
		#firewall-domain-cells = <0>;
		sai = <SAI_IA_EMMC_VAL>;
		group_fw_dom_emmc {
		rule_fw_dom_emmc_1 { /*  50  in FW_DDR_Rules */
			op       = <NOC_FW_OP_ADD>;
			sai      = <SAI_IA_EMMC_VAL>;
			base     = <NOC_FW_SPECIAL_REGION  NOC_FW_DDR_GENERIC_RW_START>;
			end      = <NOC_FW_SPECIAL_REGION  NOC_FW_DDR_GENERIC_RW_END>;
			perm     = <NOC_FW_F_RW>;
		};
		};
	};
	fw_dom_pp:fw_dom_pp {
		#firewall-domain-cells = <0>;
		sai = <SAI_IA_PP_VAL>;
		group_fw_dom_pp {
		rule_fw_dom_pp_1 { /*  51  in FW_DDR_Rules */
			op       = <NOC_FW_OP_ADD>;
			sai      = <SAI_IA_PP_VAL>;
			base     = <0xA0000000 NOC_FW_SYSPOOL_START>; /* NOC_FW_NONCOHERENT|NOC_FW_SPECIAL_REGION  NOC_FW_SYSPOOL_START */
			end      = <0xA0000000 NOC_FW_SYSPOOL_END>; /* NOC_FW_NONCOHERENT|NOC_FW_SPECIAL_REGION  NOC_FW_SYSPOOL_END */
			perm     = <NOC_FW_F_RW>;
		};
		rule_fw_dom_pp_2 { /*  54  in FW_DDR_Rules */
			op       = <NOC_FW_OP_ADD>;
			sai      = <SAI_IA_PP_VAL>;
			base     = <NOC_FW_SPECIAL_REGION  NOC_FW_CPUPOOL_START>;
			end      = <NOC_FW_SPECIAL_REGION  NOC_FW_CPUPOOL_END>;
			perm     = <NOC_FW_F_RW>;
		};
		};
	};
	fw_dom_epu:fw_dom_epu {
		#firewall-domain-cells = <0>;
		sai = <SAI_IA_EPU_VAL>;
		group_fw_dom_epu {
		};
	};
	fw_dom_vpn:fw_dom_vpn {
		#firewall-domain-cells = <0>;
		sai = <SAI_IA_ARCVPN_VAL>;
		group_fw_dom_vpn {
		rule_fw_dom_vpn_1 { /*  56  in FW_PERI_Rules */
			op       = <NOC_FW_OP_ADD>;
			sai      = <SAI_IA_ARCVPN_VAL>;
			base     = <0x0  0xED600000>;
			end      = <0x0  0xED6FFFFF>;
			perm     = <NOC_FW_F_RW>;
		};
		rule_fw_dom_vpn_2 { /*  78  in FW_PERI_Rules */
			op       = <NOC_FW_OP_ADD>;
			sai      = <SAI_IA_ARCVPN_VAL>;
			base     = <0x0  0xE0020000>;
			end      = <0x0  0xE0020FFF>;
			perm     = <NOC_FW_F_RW>;
		};
		rule_fw_dom_vpn_3 { /*  4  in FW_ETHNoC_Rules */
			op       = <NOC_FW_OP_ADD>;
			sai      = <SAI_IA_ARCVPN_VAL>;
			base     = <0xA0000000 NOC_FW_SYSPOOL_START>; /* NOC_FW_NONCOHERENT|NOC_FW_SPECIAL_REGION  NOC_FW_SYSPOOL_START */
			end      = <0xA0000000 NOC_FW_SYSPOOL_END>; /* NOC_FW_NONCOHERENT|NOC_FW_SPECIAL_REGION  NOC_FW_SYSPOOL_END */
			perm     = <NOC_FW_F_RW>;
		};
		rule_fw_dom_vpn_4 { /*  74  in FW_DDR_Rules */
			op       = <NOC_FW_OP_ADD>;
			sai      = <SAI_IA_ARCVPN_VAL>;
			base     = <NOC_FW_SPECIAL_REGION  NOC_FW_CPUPOOL_START>;
			end      = <NOC_FW_SPECIAL_REGION  NOC_FW_CPUPOOL_END>;
			perm     = <NOC_FW_F_R>;
		};
		};
	};
	fw_dom_dmar:fw_dom_dmar {
		#firewall-domain-cells = <0>;
		sai = <SAI_IA_DMAR_VAL>;
		group_fw_dom_dmar {
		rule_fw_dom_dmar_1 { /*  5  in FW_SSB_Rules */
			op       = <NOC_FW_OP_ADD>;
			sai      = <SAI_IA_DMAR_VAL>;
			base     = <0x0  0xECD00000>;
			end      = <0x0  0xECD7FFFF>;
			perm     = <NOC_FW_F_RW>;
		};
		rule_fw_dom_dmar_2 { /*  8  in FW_ETHNoC_Rules */
			op       = <NOC_FW_OP_ADD>;
			sai      = <SAI_IA_DMAR_VAL>;
			base     = <0xA0000000 NOC_FW_SYSPOOL_START>; /* NOC_FW_NONCOHERENT|NOC_FW_SPECIAL_REGION  NOC_FW_SYSPOOL_START */
			end      = <0xA0000000 NOC_FW_SYSPOOL_END>; /* NOC_FW_NONCOHERENT|NOC_FW_SPECIAL_REGION  NOC_FW_SYSPOOL_END */
			perm     = <NOC_FW_F_W>;
		};
		};
	};
};
